VERSION ""

NS_ :

BS_:

BU_: BOOT STEER PEDAL TER_CMDS FRONT_AXLE IMU LVBMS ECU CHARGER TireTemps REFRI Control

BO_ 2147484162 BOOT_TX: 8 BOOT
 SG_ HEX_SIZE m1 : 40|24@1+ (1,0) [0|3] "" Vector__XXX
 SG_ HEX_CRC m1 : 8|32@1+ (1,0) [0|3] "" Vector__XXX
 SG_ NODE_ID : 4|4@1+ (1,0) [0|3] "" Vector__XXX
 SG_ BOOT_CMD M : 0|4@1+ (1,0) [0|3] "" Vector__XXX

BO_ 2147484161 BOOT_RX: 8 BOOT
 SG_ NACK m1 : 4|1@1+ (1,0) [0|1] "" Vector__XXX
 SG_ ACK m0 : 4|1@1+ (1,0) [0|1] "" Vector__XXX
 SG_ PERCENT m2 : 4|8@1+ (1,0) [0|1] "" Vector__XXX
 SG_ BOOT_CMD M : 0|4@1+ (1,0) [0|1] "" Vector__XXX

BO_ 2147484160 BOOT_DATA: 8 BOOT
 SG_ ADRESS : 32|32@1+ (1,0) [0|1] "" Vector__XXX
 SG_ DATA : 0|32@1+ (1,0) [0|1] "" Vector__XXX

BO_ 1 COMMAND: 8 TER_CMDS
 SG_ speedLimit m193 : 24|8@1+ (1,0) [1|120] "km/h" Vector__XXX
 SG_ cfgTractionControl m194 : 24|8@1+ (1,0) [0|1] "" Vector__XXX
 SG_ trqLimit m193 : 16|8@1+ (1,0) [1|180] "N/m" Vector__XXX
 SG_ cfgMode m194 : 16|8@1+ (1,0) [0|1] "" Vector__XXX
 SG_ kwLimit m193 : 8|8@1+ (1,0) [1|120] "kW" Vector__XXX
 SG_ cfgLimiter m194 : 8|8@1+ (1,0) [0|1] "" Vector__XXX
 SG_ VALUE m128 : 8|32@1+ (1,0) [0|1] "" Vector__XXX
 SG_ ONOFF m64 : 8|8@1+ (1,0) [0|1] "" Vector__XXX
 SG_ CMD M : 0|8@1+ (1,0) [0|1] "" Vector__XXX

BO_ 2 RESPONSE: 8 TER_CMDS
 SG_ CODE : 56|8@1+ (1,0) [0|1] "" Vector__XXX
 SG_ CMD M : 0|8@1+ (1,0) [0|1] "" Vector__XXX

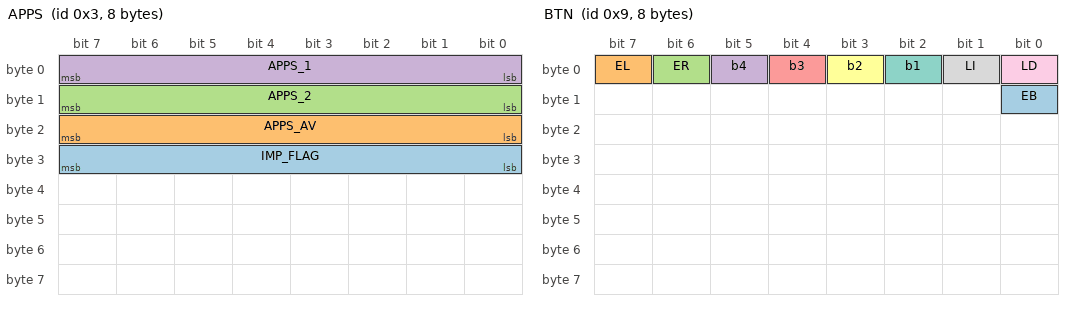
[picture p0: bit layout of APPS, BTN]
BO_ 3 APPS: 8 PEDAL
 SG_ IMP_FLAG : 24|8@1+ (1,0) [0|255] "" Vector__XXX
 SG_ APPS_AV : 16|8@1+ (1,0) [0|255] "" Vector__XXX
 SG_ APPS_2 : 8|8@1+ (1,0) [0|255] "" Vector__XXX
 SG_ APPS_1 : 0|8@1+ (1,0) [0|255] "" Vector__XXX

BO_ 4 BPPS: 8 PEDAL
 SG_ BPPS : 0|16@1+ (0.01,0) [0|1] "Bar" Vector__XXX

BO_ 5 STEER: 8 PEDAL
 SG_ ANGLE : 0|16@1- (1,0) [-360|360] "Grad" Vector__XXX

BO_ 9 BTN: 8 STEER
 SG_ EB : 8|1@1+ (1,0) [0|0] "" Vector__XXX
 SG_ EL : 7|1@1+ (1,0) [0|0] "" Vector__XXX
 SG_ ER : 6|1@1+ (1,0) [0|0] "" Vector__XXX
 SG_ b4 : 5|1@1+ (1,0) [0|0] "" Vector__XXX
 SG_ b3 : 4|1@1+ (1,0) [0|0] "" Vector__XXX
 SG_ b2 : 3|1@1+ (1,0) [0|0] "" Vector__XXX
 SG_ b1 : 2|1@1+ (1,0) [0|0] "" Vector__XXX
 SG_ LI : 1|1@1+ (1,0) [0|0] "" Vector__XXX
 SG_ LD : 0|1@1+ (1,0) [0|0] "" Vector__XXX

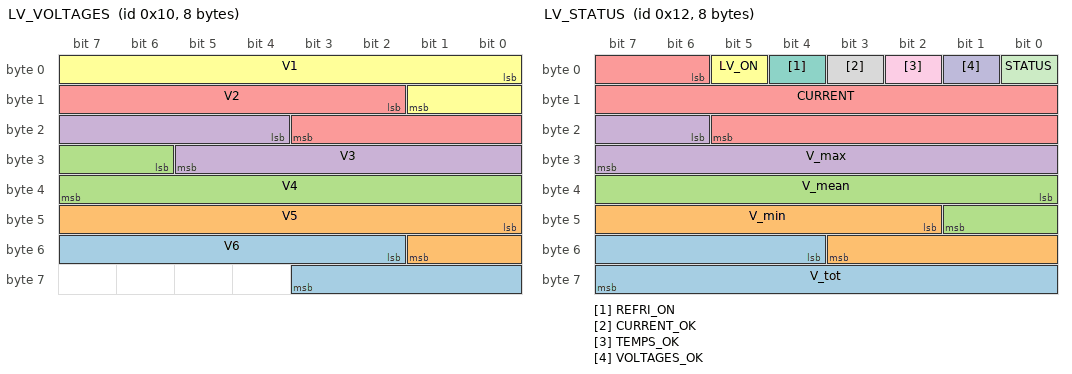
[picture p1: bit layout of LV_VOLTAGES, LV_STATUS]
BO_ 16 LV_VOLTAGES: 8 LVBMS
 SG_ V6 : 50|10@1+ (0.01,0) [0|1] "V" Vector__XXX
 SG_ V5 : 40|10@1+ (0.01,0) [0|1] "V" Vector__XXX
 SG_ V4 : 30|10@1+ (0.01,0) [0|1] "V" Vector__XXX
 SG_ V3 : 20|10@1+ (0.01,0) [0|1] "V" Vector__XXX
 SG_ V2 : 10|10@1+ (0.01,0) [0|1] "V" Vector__XXX
 SG_ V1 : 0|10@1+ (0.01,0) [0|1] "V" Vector__XXX

BO_ 17 LV_TEMPS: 6 LVBMS
 SG_ T3 : 32|16@1+ (0.1,0) [0|1] "Grad" Vector__XXX
 SG_ T2 : 16|16@1+ (0.1,0) [0|1] "Grad" Vector__XXX
 SG_ T1 : 0|16@1+ (0.1,0) [0|1] "Grad" Vector__XXX

BO_ 18 LV_STATUS: 8 LVBMS
 SG_ V_tot : 52|12@1+ (0.01,0) [0|0] "" Vector__XXX
 SG_ V_min : 42|10@1+ (0.01,0) [0|0] "" Vector__XXX
 SG_ V_mean : 32|10@1+ (0.01,0) [0|0] "" Vector__XXX
 SG_ V_max : 22|10@1+ (0.01,0) [0|0] "" Vector__XXX
 SG_ CURRENT : 6|16@1+ (0.1,0) [0|1] "A" Vector__XXX
 SG_ LV_ON : 5|1@1+ (1,0) [0|1] "" Vector__XXX
 SG_ REFRI_ON : 4|1@1+ (1,0) [0|1] "" Vector__XXX
 SG_ CURRENT_OK : 3|1@1+ (1,0) [0|0] "" Vector__XXX
 SG_ TEMPS_OK : 2|1@1+ (1,0) [0|1] "" Vector__XXX
 SG_ VOLTAGES_OK : 1|1@1+ (1,0) [0|0] "" Vector__XXX
 SG_ STATUS : 0|1@1+ (1,0) [0|0] "" Vector__XXX

BO_ 2147483667 LV_INFO: 8 LVBMS
 SG_ battDuration : 12|12@1+ (1,0) [0|1] "min" Vector__XXX
 SG_ SOC : 0|12@1+ (0.1,0) [0|1] "%" Vector__XXX

BO_ 35 Front_Susp: 8 FRONT_AXLE
 SG_ flDisp : 16|16@1- (0.1,0) [0|1] "mm" Vector__XXX
 SG_ frDisp : 0|16@1- (0.1,0) [0|1] "mm" Vector__XXX

BO_ 36 Front_TempsR: 8 FRONT_AXLE
 SG_ TempL : 16|16@1+ (0.1,0) [0|1] "grad" Vector__XXX
 SG_ TempR : 0|16@1+ (0.1,0) [0|1] "grad" Vector__XXX

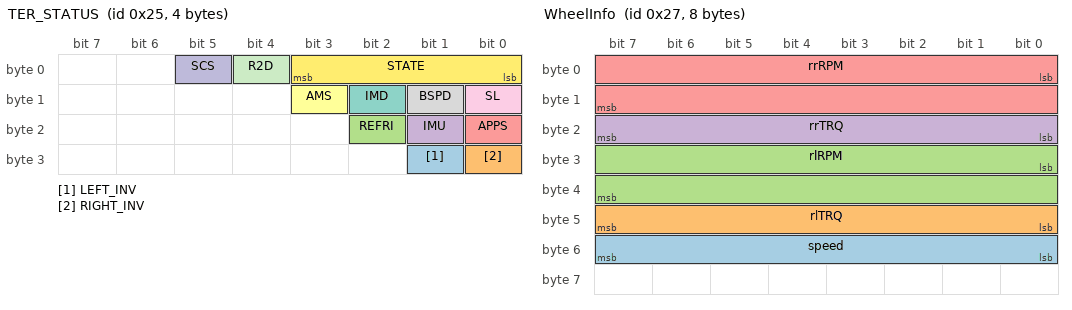
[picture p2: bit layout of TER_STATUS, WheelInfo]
BO_ 37 TER_STATUS: 4 ECU
 SG_ LEFT_INV : 25|1@1+ (1,0) [0|1] "" Vector__XXX
 SG_ RIGHT_INV : 24|1@1+ (1,0) [0|1] "" Vector__XXX
 SG_ REFRI : 18|1@1+ (1,0) [0|1] "" Vector__XXX
 SG_ IMU : 17|1@1+ (1,0) [0|1] "" Vector__XXX
 SG_ APPS : 16|1@1+ (1,0) [0|1] "" Vector__XXX
 SG_ AMS : 11|1@1+ (1,0) [0|1] "" Vector__XXX
 SG_ IMD : 10|1@1+ (1,0) [0|0] "" Vector__XXX
 SG_ BSPD : 9|1@1+ (1,0) [0|0] "" Vector__XXX
 SG_ SL : 8|1@1+ (1,0) [0|1] "" Vector__XXX
 SG_ SCS : 5|1@1+ (1,0) [0|1] "" Vector__XXX
 SG_ R2D : 4|1@1+ (1,0) [0|1] "" Vector__XXX
 SG_ STATE : 0|4@1+ (1,0) [0|1] "" Vector__XXX

BO_ 2147483686 ECU_CONFIG: 8 ECU
 SG_ TRQ_LIMIT m8 : 8|8@1+ (1,0) [0|1] "NM" Vector__XXX
 SG_ TRQ_KP m5 : 8|32@1- (1,0) [0|1] "" Vector__XXX
 SG_ TRQ_KI m6 : 8|32@1- (1,0) [0|1] "" Vector__XXX
 SG_ TRQ_KD m7 : 8|32@1- (1,0) [0|1] "" Vector__XXX
 SG_ TRACTION_CONTROL m4 : 8|8@1+ (1,0) [0|1] "" Vector__XXX
 SG_ SCS_ENABLE m0 : 8|1@1+ (1,0) [0|1] "" Vector__XXX
 SG_ REGEN_TRQ_SLOPE m24 : 8|8@1+ (1,0) [0|1] "" Vector__XXX
 SG_ REGEN_THR_SPEED m22 : 8|8@1+ (1,0) [0|1] "" Vector__XXX
 SG_ REGEN_THR_RPM m23 : 8|16@1+ (1,0) [0|1] "" Vector__XXX
 SG_ REGEN_MODE m25 : 8|8@1+ (1,0) [0|1] "" Vector__XXX
 SG_ REGEN_MAX_POSITIVE_TRQ_THR m26 : 8|8@1+ (1,0) [0|1] "" Vector__XXX
 SG_ REGEN_MAX_TRQ m18 : 8|8@1+ (1,0) [0|1] "" Vector__XXX
 SG_ REGEN_MAX_CURRENT m21 : 8|16@1- (1,0) [0|1] "" Vector__XXX
 SG_ REGEN_MAX_CELL_VOLT m19 : 8|16@1+ (1,0) [0|1] "mV" Vector__XXX
 SG_ REGEN_MAX_CELL_TEMP m20 : 8|8@1+ (1,0) [0|1] "" Vector__XXX
 SG_ REGEN_ENABLE m17 : 8|8@1+ (1,0) [0|1] "" Vector__XXX
 SG_ R2D_BRAKE m1 : 8|8@1+ (1,0) [0|1] "Bar" Vector__XXX
 SG_ LIMITER m2 : 8|8@1+ (1,0) [0|1] "" Vector__XXX
 SG_ FLAP_R_REVERSE m13 : 8|8@1+ (1,0) [0|1] "0" Vector__XXX
 SG_ FLAP_R_OFFSET m11 : 8|16@1- (1,0) [0|1] "Âº" Vector__XXX
 SG_ FLAP_PEDAL_SETPOINT m15 : 8|8@1+ (1,0) [0|1] "0" Vector__XXX
 SG_ FLAP_L_REVERSE m12 : 8|8@1+ (1,0) [0|1] "0" Vector__XXX
 SG_ FLAP_L_OFFSET m10 : 8|16@1- (1,0) [0|1] "Âº" Vector__XXX
 SG_ FLAP_ENABLE m14 : 8|8@1+ (1,0) [0|1] "0" Vector__XXX
 SG_ EEPROM m9 : 8|8@1+ (1,0) [0|1] "" Vector__XXX
 SG_ DRIVING_MODE m3 : 8|8@1+ (1,0) [0|1] "" Vector__XXX
 SG_ ENTRY M : 0|8@1+ (1,0) [0|1] "" Vector__XXX

BO_ 39 WheelInfo: 8 ECU
 SG_ speed : 48|8@1+ (1,0) [0|1] "" Vector__XXX
 SG_ rlTRQ : 40|8@1+ (1,0) [0|1] "" Vector__XXX
 SG_ rlRPM : 24|16@1- (1,0) [0|1] "" Vector__XXX
 SG_ rrTRQ : 16|8@1+ (1,0) [0|1] "" Vector__XXX
 SG_ rrRPM : 0|16@1- (1,0) [0|1] "" Vector__XXX

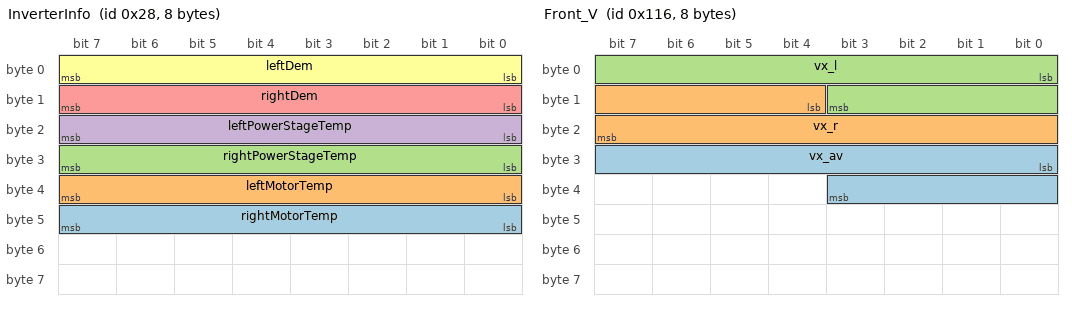
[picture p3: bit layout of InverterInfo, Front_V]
BO_ 40 InverterInfo: 8 ECU
 SG_ rightMotorTemp : 40|8@1+ (1,0) [0|1] "" Vector__XXX
 SG_ leftMotorTemp : 32|8@1+ (1,0) [0|1] "" Vector__XXX
 SG_ rightPowerStageTemp : 24|8@1+ (1,0) [0|1] "" Vector__XXX
 SG_ leftPowerStageTemp : 16|8@1+ (1,0) [0|1] "" Vector__XXX
 SG_ rightDem : 8|8@1+ (1,0) [0|1] "" Vector__XXX
 SG_ leftDem : 0|8@1+ (1,0) [0|1] "" Vector__XXX

BO_ 2147483689 Front_TempsL: 8 FRONT_AXLE
 SG_ TempL : 16|16@1+ (0.1,0) [0|1] "grad" Vector__XXX
 SG_ TempR : 0|16@1+ (0.1,0) [0|1] "grad" Vector__XXX

BO_ 2147483690 Rear_Susp: 8 FRONT_AXLE
 SG_ rrDisp : 16|16@1- (0.1,0) [0|1] "mm" Vector__XXX
 SG_ rlDisp : 0|16@1- (0.1,0) [0|1] "mm" Vector__XXX

BO_ 277 Front_RPM: 8 FRONT_AXLE
 SG_ RPM_R : 16|16@1+ (1,0) [0|1] "" Vector__XXX
 SG_ RPM_L : 0|16@1+ (1,0) [0|1] "" Vector__XXX

BO_ 278 Front_V: 8 FRONT_AXLE
 SG_ vx_av : 24|12@1+ (0.01,0) [0|1] "" Vector__XXX
 SG_ vx_r : 12|12@1+ (0.01,0) [0|1] "" Vector__XXX
 SG_ vx_l : 0|12@1+ (0.01,0) [0|1] "" Vector__XXX

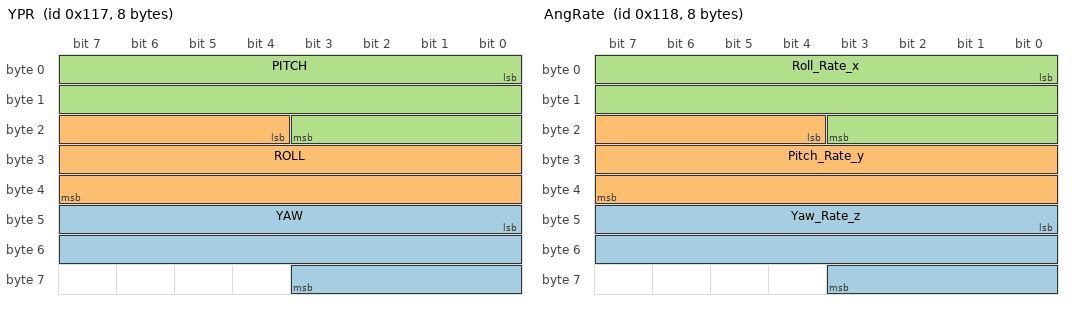
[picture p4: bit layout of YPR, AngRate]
BO_ 279 YPR: 8 IMU
 SG_ YAW : 40|20@1- (0.01,0) [0|1] "" Vector__XXX
 SG_ ROLL : 20|20@1- (0.01,0) [0|1] "" Vector__XXX
 SG_ PITCH : 0|20@1- (0.01,0) [0|1] "" Vector__XXX

BO_ 280 AngRate: 8 IMU
 SG_ Yaw_Rate_z : 40|20@1- (0.001,0) [0|1] "" Vector__XXX
 SG_ Pitch_Rate_y : 20|20@1- (0.001,0) [0|1] "" Vector__XXX
 SG_ Roll_Rate_x : 0|20@1- (0.001,0) [0|1] "" Vector__XXX

BO_ 281 GPS_Lat_Long: 8 IMU
 SG_ Longitude : 32|32@1- (1e-07,0) [0|1] "" Vector__XXX
 SG_ Latitude : 0|32@1- (1e-07,0) [0|1] "" Vector__XXX

BO_ 288 GPS_Altitude_Pres: 8 IMU
 SG_ Barometric_Pressure : 32|16@1- (1e-07,0) [0|1] "" Vector__XXX
 SG_ Altidude : 0|32@1- (1e-07,0) [0|1] "" Vector__XXX

BO_ 289 Accel: 8 IMU
 SG_ a_z : 32|16@1- (0.001,0) [0|1] "" Vector__XXX
 SG_ a_y : 16|16@1- (0.001,0) [0|1] "" Vector__XXX
 SG_ a_x : 0|16@1- (0.001,0) [0|1] "" Vector__XXX

BO_ 290 Mag: 8 IMU
 SG_ Heading : 0|16@1- (0.01,0) [0|1] "" Vector__XXX

BO_ 291 VelBody: 8 IMU
 SG_ v_z : 32|16@1- (0.001,0) [0|1] "" Vector__XXX
 SG_ v_y : 16|16@1- (0.001,0) [0|1] "" Vector__XXX
 SG_ v_x : 0|16@1- (0.001,0) [0|1] "" Vector__XXX

BO_ 292 ImuStatus: 8 IMU
 SG_ VelU : 32|16@1- (0.001,0) [0|1] "" Vector__XXX
 SG_ PosU : 16|16@1- (0.001,0) [0|1] "" Vector__XXX
 SG_ Status : 0|16@1- (1,0) [0|1] "" Vector__XXX

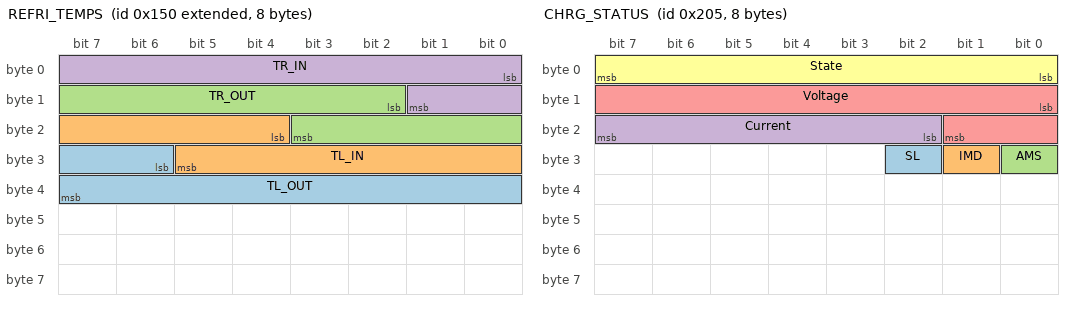
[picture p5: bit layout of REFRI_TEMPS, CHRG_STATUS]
BO_ 2147483984 REFRI_TEMPS: 8 REFRI
 SG_ TL_OUT : 30|10@1+ (0.1,0) [0|1] "C" Vector__XXX
 SG_ TL_IN : 20|10@1+ (0.1,0) [0|1] "C" Vector__XXX
 SG_ TR_OUT : 10|10@1+ (0.1,0) [0|1] "C" Vector__XXX
 SG_ TR_IN : 0|10@1+ (0.1,0) [0|1] "C" Vector__XXX

BO_ 2147483985 REFRI_CONFIG: 8 REFRI
 SG_ TARGET_TEMP_ACCU m7 : 8|8@1+ (1,0) [0|1] "ÂºC" Vector__XXX
 SG_ TARGET_TEMP m3 : 8|8@1+ (1,0) [0|1] "ÂºC" Vector__XXX
 SG_ POWER_ACCU m4 : 8|8@1+ (1,0) [0|1] "" Vector__XXX
 SG_ POWER m0 : 8|8@1+ (1,0) [0|1] "" Vector__XXX
 SG_ MODE_ACCU m6 : 8|8@1+ (1,0) [0|1] "" Vector__XXX
 SG_ MODE m2 : 8|8@1+ (1,0) [0|1] "" Vector__XXX
 SG_ INTENSITY_ACCU m5 : 8|8@1+ (1,0) [0|100] "%" Vector__XXX
 SG_ INTENSITY m1 : 8|8@1+ (1,0) [0|100] "%" Vector__XXX
 SG_ ENTRY M : 0|8@1+ (1,0) [0|1] "" Vector__XXX

BO_ 2147483986 REFRI_RPM: 8 REFRI
 SG_ ACCU_RPM : 32|16@1+ (1,0) [0|1] "rpm" Vector__XXX
 SG_ R_RPM : 16|16@1+ (1,0) [0|1] "rpm" Vector__XXX
 SG_ L_RPM : 0|16@1+ (1,0) [0|1] "rpm" Vector__XXX

BO_ 2147483987 REFRI_STATUS: 8 REFRI
 SG_ MODE : 16|2@1+ (1,0) [0|1] "" Vector__XXX
 SG_ CURRENT : 0|16@1+ (0.1,0) [0|1] "" Vector__XXX

BO_ 517 CHRG_STATUS: 8 CHARGER
 SG_ SL : 26|1@1+ (1,0) [0|1] "A" Vector__XXX
 SG_ IMD : 25|1@1+ (1,0) [0|1] "A" Vector__XXX
 SG_ AMS : 24|1@1+ (1,0) [0|1] "A" Vector__XXX
 SG_ Current : 18|6@1+ (1,0) [0|1] "A" Vector__XXX
 SG_ Voltage : 8|10@1+ (1,0) [0|1] "V" Vector__XXX
 SG_ State : 0|8@1+ (1,0) [0|1] "" Vector__XXX

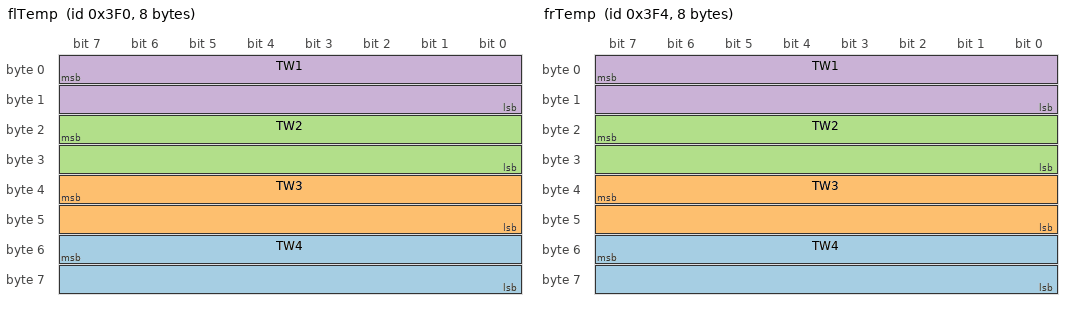
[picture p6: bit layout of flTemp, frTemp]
BO_ 1008 flTemp: 8 TireTemps
 SG_ TW4 : 55|16@0- (0.1,0) [-3276.8|3276.7] "" Vector__XXX
 SG_ TW3 : 39|16@0- (0.1,0) [-3276.8|3276.7] "" Vector__XXX
 SG_ TW2 : 23|16@0- (0.1,0) [-3276.8|3276.7] "" Vector__XXX
 SG_ TW1 : 7|16@0- (0.1,0) [-3276.8|3276.7] "" Vector__XXX

BO_ 1012 frTemp: 8 TireTemps
 SG_ TW4 : 55|16@0- (0.1,0) [-3276.8|3276.7] "" Vector__XXX
 SG_ TW3 : 39|16@0- (0.1,0) [-3276.8|3276.7] "" Vector__XXX
 SG_ TW2 : 23|16@0- (0.1,0) [-3276.8|3276.7] "" Vector__XXX
 SG_ TW1 : 7|16@0- (0.1,0) [-3276.8|3276.7] "" Vector__XXX

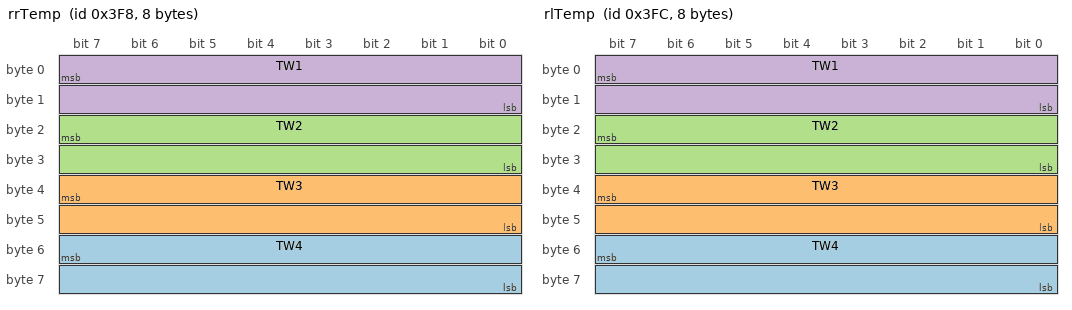
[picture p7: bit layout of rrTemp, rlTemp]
BO_ 1016 rrTemp: 8 TireTemps
 SG_ TW4 : 55|16@0- (0.1,0) [-3276.8|3276.7] "" Vector__XXX
 SG_ TW3 : 39|16@0- (0.1,0) [-3276.8|3276.7] "" Vector__XXX
 SG_ TW2 : 23|16@0- (0.1,0) [-3276.8|3276.7] "" Vector__XXX
 SG_ TW1 : 7|16@0- (0.1,0) [-3276.8|3276.7] "" Vector__XXX

BO_ 1020 rlTemp: 8 TireTemps
 SG_ TW4 : 55|16@0- (0.1,0) [-3276.8|3276.7] "" Vector__XXX
 SG_ TW3 : 39|16@0- (0.1,0) [-3276.8|3276.7] "" Vector__XXX
 SG_ TW2 : 23|16@0- (0.1,0) [-3276.8|3276.7] "" Vector__XXX
 SG_ TW1 : 7|16@0- (0.1,0) [-3276.8|3276.7] "" Vector__XXX

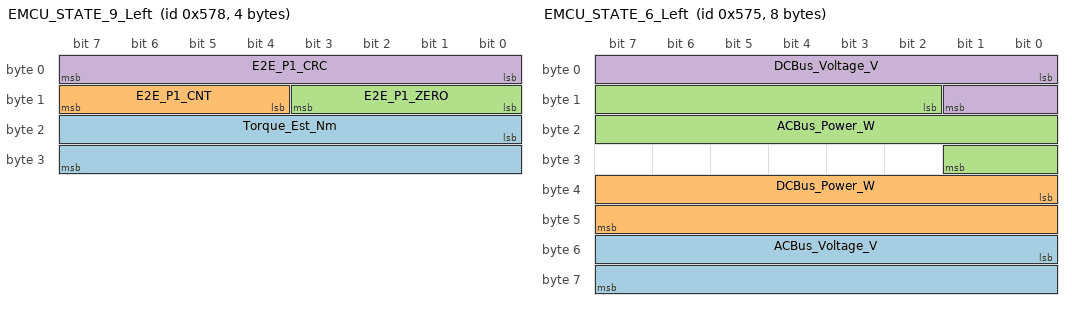
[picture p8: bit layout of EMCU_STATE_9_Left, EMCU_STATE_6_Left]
BO_ 1400 EMCU_STATE_9_Left: 4 Vector__XXX
 SG_ Torque_Est_Nm : 16|16@1- (1,0) [-32768|32767] "" Vector__XXX
 SG_ E2E_P1_CNT : 12|4@1+ (1,0) [0|15] "" Vector__XXX
 SG_ E2E_P1_ZERO : 8|4@1+ (1,0) [0|15] "" Vector__XXX
 SG_ E2E_P1_CRC : 0|8@1+ (1,0) [0|255] "" Vector__XXX

BO_ 1399 EMCU_STATE_8_Left: 6 Vector__XXX
 SG_ Setpoint_App_Q_A : 32|16@1- (0.03125,0) [-1024|1023.97] "" Vector__XXX
 SG_ Setpoint_App_D_A : 16|16@1- (0.03125,0) [-1024|1023.97] "" Vector__XXX
 SG_ Torque_Max_Feas_Ndm : 0|16@1- (1,0) [-32768|32767] "" Vector__XXX

BO_ 1398 EMCU_STATE_7_Left: 2 Vector__XXX
 SG_ Dem : 0|16@1+ (1,0) [0|65535] "" Vector__XXX

BO_ 1397 EMCU_STATE_6_Left: 8 Vector__XXX
 SG_ ACBus_Voltage_V : 48|16@1- (1,0) [-32768|32767] "" Vector__XXX
 SG_ DCBus_Power_W : 32|16@1- (1,0) [-32768|32767] "" Vector__XXX
 SG_ ACBus_Power_W : 10|16@1- (32.767,0) [-1073710|1073680] "" Vector__XXX
 SG_ DCBus_Voltage_V : 0|10@1+ (1,0) [0|1023] "" Vector__XXX

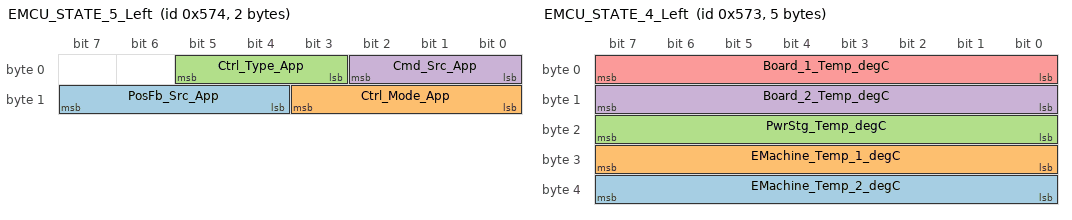
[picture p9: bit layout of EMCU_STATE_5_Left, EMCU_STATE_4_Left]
BO_ 1396 EMCU_STATE_5_Left: 2 Vector__XXX
 SG_ PosFb_Src_App : 12|4@1+ (1,0) [0|15] "" Vector__XXX
 SG_ Ctrl_Mode_App : 8|4@1+ (1,0) [0|15] "" Vector__XXX
 SG_ Ctrl_Type_App : 3|3@1+ (1,0) [0|7] "" Vector__XXX
 SG_ Cmd_Src_App : 0|3@1+ (1,0) [0|7] "" Vector__XXX

BO_ 1395 EMCU_STATE_4_Left: 5 Vector__XXX
 SG_ EMachine_Temp_2_degC : 32|8@1- (1,80) [-48|207] "" Vector__XXX
 SG_ EMachine_Temp_1_degC : 24|8@1- (1,80) [-48|207] "" Vector__XXX
 SG_ PwrStg_Temp_degC : 16|8@1- (1,80) [-48|207] "" Vector__XXX
 SG_ Board_2_Temp_degC : 8|8@1- (1,80) [-48|207] "" Vector__XXX
 SG_ Board_1_Temp_degC : 0|8@1- (1,80) [-48|207] "" Vector__XXX

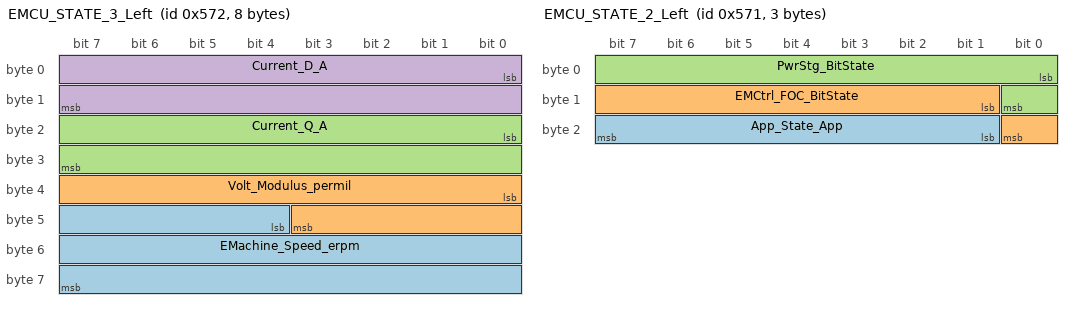
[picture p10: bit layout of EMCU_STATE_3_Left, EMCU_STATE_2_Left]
BO_ 1394 EMCU_STATE_3_Left: 8 Vector__XXX
 SG_ EMachine_Speed_erpm : 44|20@1- (1,0) [-524288|524287] "" Vector__XXX
 SG_ Volt_Modulus_permil : 32|12@1+ (1,0) [0|4095] "" Vector__XXX
 SG_ Current_Q_A : 16|16@1- (0.03125,0) [-1024|1023.97] "" Vector__XXX
 SG_ Current_D_A : 0|16@1- (0.03125,0) [-1024|1023.97] "" Vector__XXX

BO_ 1393 EMCU_STATE_2_Left: 3 Vector__XXX
 SG_ App_State_App : 17|7@1+ (1,0) [0|127] "" Vector__XXX
 SG_ EMCtrl_FOC_BitState : 9|8@1+ (1,0) [0|255] "" Vector__XXX
 SG_ PwrStg_BitState : 0|9@1+ (1,0) [0|511] "" Vector__XXX

BO_ 1392 EMCU_STATE_1_Left: 5 Vector__XXX
 SG_ CPU_Load : 32|8@1+ (1,0) [0|255] "" Vector__XXX
 SG_ Uptime_ms : 0|32@1+ (1,0) [0|2704] "" Vector__XXX

BO_ 1653 EMCU_SETPOINT_6_Left: 2 Vector__XXX
 SG_ PWM_Freq_KHz : 0|16@1+ (1,0) [0|65535] "" Vector__XXX

BO_ 1651 EMCU_SETPOINT_4_Left: 4 Vector__XXX
 SG_ Speed_erpm : 0|32@1- (1,0) [-2147480000|2147480000] "" Vector__XXX

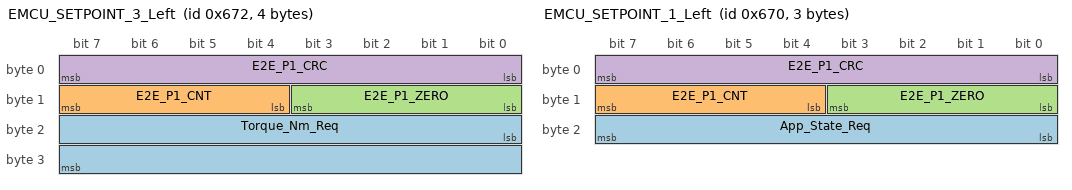
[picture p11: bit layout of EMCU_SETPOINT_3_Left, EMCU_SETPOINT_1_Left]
BO_ 1650 EMCU_SETPOINT_3_Left: 4 Vector__XXX
 SG_ Torque_Nm_Req : 16|16@1- (1,0) [-32768|32767] "" Vector__XXX
 SG_ E2E_P1_CNT : 12|4@1+ (1,0) [0|15] "" Vector__XXX
 SG_ E2E_P1_ZERO : 8|4@1+ (1,0) [0|15] "" Vector__XXX
 SG_ E2E_P1_CRC : 0|8@1+ (1,0) [0|255] "" Vector__XXX

BO_ 1649 EMCU_SETPOINT_2_Left: 4 Vector__XXX
 SG_ Current_Q_A_Req : 16|16@1- (0.03125,0) [-1024|1023.97] "" Vector__XXX
 SG_ Current_D_A_Req : 0|16@1- (0.03125,0) [-1024|1023.97] "" Vector__XXX

BO_ 1648 EMCU_SETPOINT_1_Left: 3 Vector__XXX
 SG_ App_State_Req : 16|8@1+ (1,0) [0|255] "" Vector__XXX
 SG_ E2E_P1_CNT : 12|4@1+ (1,0) [0|15] "" Vector__XXX
 SG_ E2E_P1_ZERO : 8|4@1+ (1,0) [0|15] "" Vector__XXX
 SG_ E2E_P1_CRC : 0|8@1+ (1,0) [0|255] "" Vector__XXX

BO_ 2147485552 EMCU_DEBUG_1_Left: 2 Vector__XXX
 SG_ EMachine_Angle_fract16 : 0|16@1+ (1,0) [0|65535] "" Vector__XXX

BO_ 1376 EMCU_STATE_1_Right: 5 Vector__XXX
 SG_ CPU_Load : 32|8@1+ (1,0) [0|255] "" Vector__XXX
 SG_ Uptime_ms : 0|32@1+ (1,0) [0|2704] "" Vector__XXX

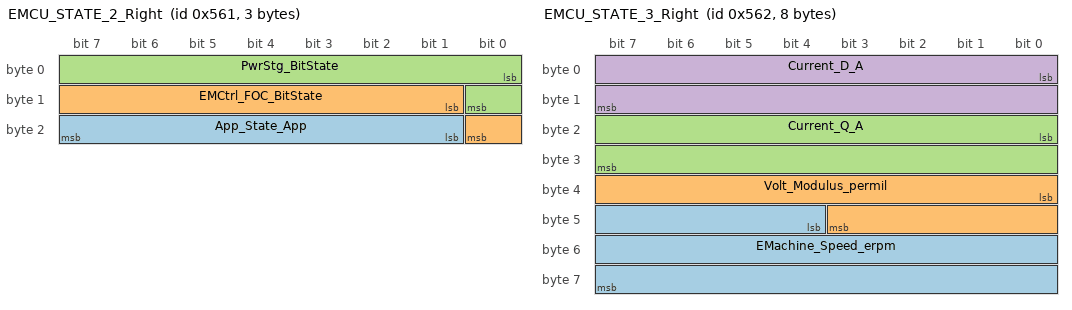
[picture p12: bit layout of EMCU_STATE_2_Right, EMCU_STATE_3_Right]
BO_ 1377 EMCU_STATE_2_Right: 3 Vector__XXX
 SG_ App_State_App : 17|7@1+ (1,0) [0|127] "" Vector__XXX
 SG_ EMCtrl_FOC_BitState : 9|8@1+ (1,0) [0|255] "" Vector__XXX
 SG_ PwrStg_BitState : 0|9@1+ (1,0) [0|511] "" Vector__XXX

BO_ 1378 EMCU_STATE_3_Right: 8 Vector__XXX
 SG_ EMachine_Speed_erpm : 44|20@1- (1,0) [-524288|524287] "" Vector__XXX
 SG_ Volt_Modulus_permil : 32|12@1+ (1,0) [0|4095] "" Vector__XXX
 SG_ Current_Q_A : 16|16@1- (0.03125,0) [-1024|1023.97] "" Vector__XXX
 SG_ Current_D_A : 0|16@1- (0.03125,0) [-1024|1023.97] "" Vector__XXX

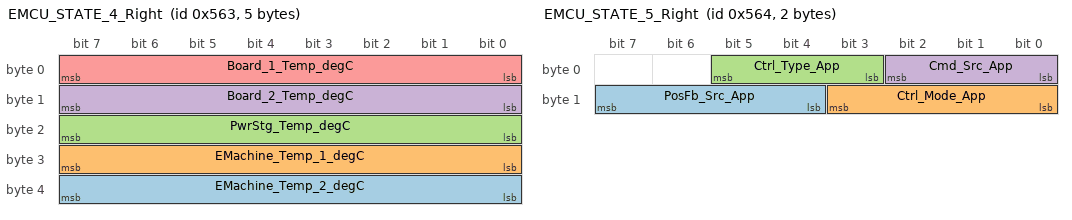
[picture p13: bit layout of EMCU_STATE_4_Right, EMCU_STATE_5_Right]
BO_ 1379 EMCU_STATE_4_Right: 5 Vector__XXX
 SG_ EMachine_Temp_2_degC : 32|8@1- (1,80) [-48|207] "" Vector__XXX
 SG_ EMachine_Temp_1_degC : 24|8@1- (1,80) [-48|207] "" Vector__XXX
 SG_ PwrStg_Temp_degC : 16|8@1- (1,80) [-48|207] "" Vector__XXX
 SG_ Board_2_Temp_degC : 8|8@1- (1,80) [-48|207] "" Vector__XXX
 SG_ Board_1_Temp_degC : 0|8@1- (1,80) [-48|207] "" Vector__XXX

BO_ 1380 EMCU_STATE_5_Right: 2 Vector__XXX
 SG_ PosFb_Src_App : 12|4@1+ (1,0) [0|15] "" Vector__XXX
 SG_ Ctrl_Mode_App : 8|4@1+ (1,0) [0|15] "" Vector__XXX
 SG_ Ctrl_Type_App : 3|3@1+ (1,0) [0|7] "" Vector__XXX
 SG_ Cmd_Src_App : 0|3@1+ (1,0) [0|7] "" Vector__XXX

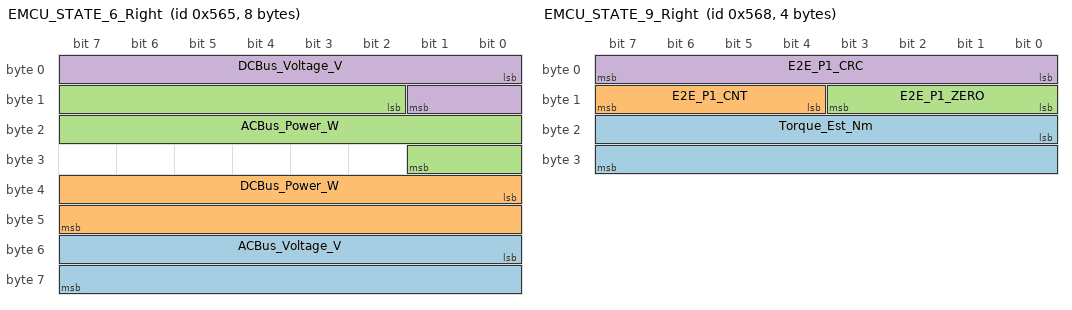
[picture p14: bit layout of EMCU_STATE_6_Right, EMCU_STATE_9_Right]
BO_ 1381 EMCU_STATE_6_Right: 8 Vector__XXX
 SG_ ACBus_Voltage_V : 48|16@1- (1,0) [-32768|32767] "" Vector__XXX
 SG_ DCBus_Power_W : 32|16@1- (1,0) [-32768|32767] "" Vector__XXX
 SG_ ACBus_Power_W : 10|16@1- (32.767,0) [-1073710|1073680] "" Vector__XXX
 SG_ DCBus_Voltage_V : 0|10@1+ (1,0) [0|1023] "" Vector__XXX

BO_ 1382 EMCU_STATE_7_Right: 2 Vector__XXX
 SG_ Dem : 0|16@1+ (1,0) [0|65535] "" Vector__XXX

BO_ 1383 EMCU_STATE_8_Right: 6 Vector__XXX
 SG_ Setpoint_App_Q_A : 32|16@1- (0.03125,0) [-1024|1023.97] "" Vector__XXX
 SG_ Setpoint_App_D_A : 16|16@1- (0.03125,0) [-1024|1023.97] "" Vector__XXX
 SG_ Torque_Max_Feas_Ndm : 0|16@1- (1,0) [-32768|32767] "" Vector__XXX

BO_ 1384 EMCU_STATE_9_Right: 4 Vector__XXX
 SG_ Torque_Est_Nm : 16|16@1- (1,0) [-32768|32767] "" Vector__XXX
 SG_ E2E_P1_CNT : 12|4@1+ (1,0) [0|15] "" Vector__XXX
 SG_ E2E_P1_ZERO : 8|4@1+ (1,0) [0|15] "" Vector__XXX
 SG_ E2E_P1_CRC : 0|8@1+ (1,0) [0|255] "" Vector__XXX

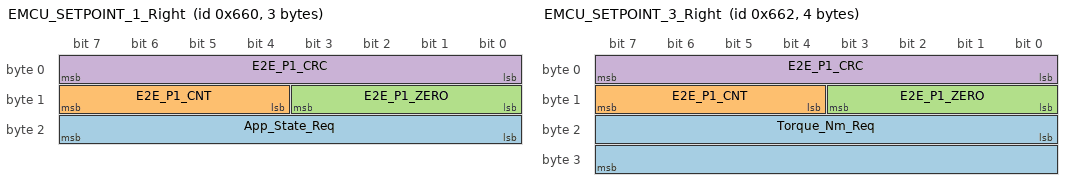
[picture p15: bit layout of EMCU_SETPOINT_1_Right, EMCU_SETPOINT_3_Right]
BO_ 1632 EMCU_SETPOINT_1_Right: 3 Vector__XXX
 SG_ App_State_Req : 16|8@1+ (1,0) [0|255] "" Vector__XXX
 SG_ E2E_P1_CNT : 12|4@1+ (1,0) [0|15] "" Vector__XXX
 SG_ E2E_P1_ZERO : 8|4@1+ (1,0) [0|15] "" Vector__XXX
 SG_ E2E_P1_CRC : 0|8@1+ (1,0) [0|255] "" Vector__XXX

BO_ 1633 EMCU_SETPOINT_2_Right: 4 Vector__XXX
 SG_ Current_Q_A_Req : 16|16@1- (0.03125,0) [-1024|1023.97] "" Vector__XXX
 SG_ Current_D_A_Req : 0|16@1- (0.03125,0) [-1024|1023.97] "" Vector__XXX

BO_ 1634 EMCU_SETPOINT_3_Right: 4 Vector__XXX
 SG_ Torque_Nm_Req : 16|16@1- (1,0) [-32768|32767] "" Vector__XXX
 SG_ E2E_P1_CNT : 12|4@1+ (1,0) [0|15] "" Vector__XXX
 SG_ E2E_P1_ZERO : 8|4@1+ (1,0) [0|15] "" Vector__XXX
 SG_ E2E_P1_CRC : 0|8@1+ (1,0) [0|255] "" Vector__XXX

BO_ 1635 EMCU_SETPOINT_4_Right: 4 Vector__XXX
 SG_ Speed_erpm : 0|32@1- (1,0) [-2147480000|2147480000] "" Vector__XXX

BO_ 1637 EMCU_SETPOINT_6_Right: 2 Vector__XXX
 SG_ PWM_Freq_KHz : 0|16@1+ (1,0) [0|65535] "" Vector__XXX

BO_ 2147485536 EMCU_DEBUG_1_Right: 2 Vector__XXX
 SG_ EMachine_Angle_fract16 : 0|16@1+ (1,0) [0|65535] "" Vector__XXX

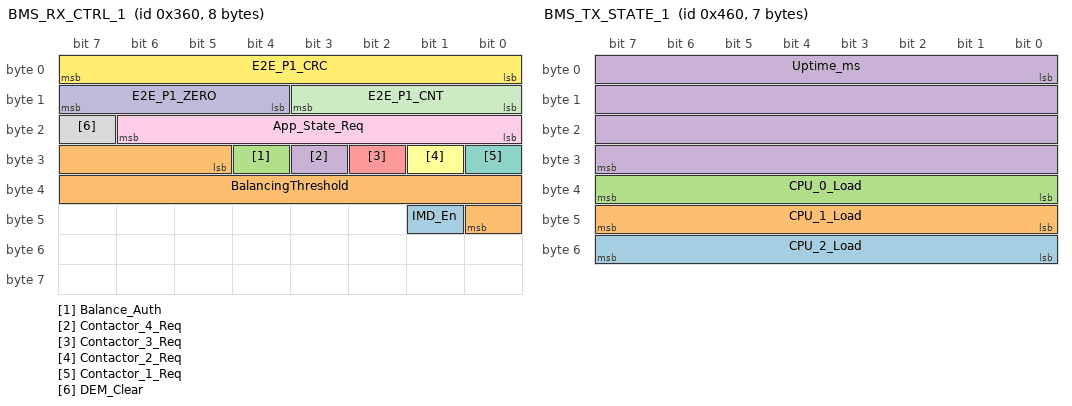
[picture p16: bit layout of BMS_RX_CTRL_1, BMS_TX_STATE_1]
BO_ 864 BMS_RX_CTRL_1: 8 Vector__XXX
 SG_ IMD_En : 41|1@1+ (1,0) [0|1] "" Vector__XXX
 SG_ BalancingThreshold : 29|12@1+ (1,405) [405|4500] "" Vector__XXX
 SG_ Balance_Auth : 28|1@1- (1,0) [0|1] "" Vector__XXX
 SG_ Contactor_4_Req : 27|1@1- (1,0) [0|1] "" Vector__XXX
 SG_ Contactor_3_Req : 26|1@1- (1,0) [0|1] "" Vector__XXX
 SG_ Contactor_2_Req : 25|1@1- (1,0) [0|1] "" Vector__XXX
 SG_ Contactor_1_Req : 24|1@1- (1,0) [0|1] "" Vector__XXX
 SG_ DEM_Clear : 23|1@1+ (1,0) [0|1] "" Vector__XXX
 SG_ App_State_Req : 16|7@1+ (1,0) [0|255] "" Vector__XXX
 SG_ E2E_P1_ZERO : 12|4@1+ (1,0) [0|15] "" Vector__XXX
 SG_ E2E_P1_CNT : 8|4@1+ (1,0) [0|15] "" Vector__XXX
 SG_ E2E_P1_CRC : 0|8@1+ (1,0) [0|255] "" Vector__XXX

BO_ 1024 BMS_TX_CMD_1: 6 Vector__XXX
 SG_ CellTemp4 m6 : 32|8@1+ (1,-40) [-40|140] "" Vector__XXX
 SG_ Cell9 m2 : 32|12@1+ (1,405) [405|4500] "" Vector__XXX
 SG_ Cell6 m1 : 32|12@1+ (1,405) [405|4500] "" Vector__XXX
 SG_ Cell3 m0 : 32|12@1+ (1,405) [405|4500] "" Vector__XXX
 SG_ Cell18 m5 : 32|12@1+ (1,405) [405|4500] "" Vector__XXX
 SG_ Cell15 m4 : 32|12@1+ (1,405) [405|4500] "" Vector__XXX
 SG_ Cell12 m3 : 32|12@1+ (1,405) [405|4500] "" Vector__XXX
 SG_ CellTemp3 m6 : 24|8@1+ (1,-40) [-40|140] "" Vector__XXX
 SG_ Cell8 m2 : 20|12@1+ (1,405) [405|4500] "" Vector__XXX
 SG_ Cell5 m1 : 20|12@1+ (1,405) [405|4500] "" Vector__XXX
 SG_ Cell2 m0 : 20|12@1+ (1,405) [405|4500] "" Vector__XXX
 SG_ Cell17 m5 : 20|12@1+ (1,405) [405|4500] "" Vector__XXX
 SG_ Cell14 m4 : 20|12@1+ (1,405) [405|4500] "" Vector__XXX
 SG_ Cell11 m3 : 20|12@1+ (1,405) [405|4500] "" Vector__XXX
 SG_ CellTemp2 m6 : 16|8@1+ (1,-40) [-40|140] "" Vector__XXX
 SG_ CellTemp1 m6 : 8|8@1+ (1,-40) [-40|140] "" Vector__XXX
 SG_ Cell7 m2 : 8|12@1+ (1,405) [405|4500] "" Vector__XXX
 SG_ Cell4 m1 : 8|12@1+ (1,405) [405|4500] "" Vector__XXX
 SG_ Cell16 m5 : 8|12@1+ (1,405) [405|4500] "" Vector__XXX
 SG_ Cell13 m4 : 8|12@1+ (1,405) [405|4500] "" Vector__XXX
 SG_ Cell10 m3 : 8|12@1+ (1,405) [405|4500] "" Vector__XXX
 SG_ Cell1 m0 : 8|12@1+ (1,405) [405|4500] "" Vector__XXX
 SG_ Cell_Cnt : 4|4@1+ (1,0) [0|15] "" Vector__XXX
 SG_ Cell_Idx M : 0|4@1+ (1,0) [0|4095] "" Vector__XXX

BO_ 1025 BMS_TX_CMD_2: 6 Vector__XXX
 SG_ CellTemp4 m6 : 32|8@1+ (1,-40) [-40|140] "" Vector__XXX
 SG_ Cell9 m2 : 32|12@1+ (1,405) [405|4500] "" Vector__XXX
 SG_ Cell6 m1 : 32|12@1+ (1,405) [405|4500] "" Vector__XXX
 SG_ Cell3 m0 : 32|12@1+ (1,405) [405|4500] "" Vector__XXX
 SG_ Cell18 m5 : 32|12@1+ (1,405) [405|4500] "" Vector__XXX
 SG_ Cell15 m4 : 32|12@1+ (1,405) [405|4500] "" Vector__XXX
 SG_ Cell12 m3 : 32|12@1+ (1,405) [405|4500] "" Vector__XXX
 SG_ CellTemp3 m6 : 24|8@1+ (1,-40) [-40|140] "" Vector__XXX
 SG_ Cell8 m2 : 20|12@1+ (1,405) [405|4500] "" Vector__XXX
 SG_ Cell5 m1 : 20|12@1+ (1,405) [405|4500] "" Vector__XXX
 SG_ Cell2 m0 : 20|12@1+ (1,405) [405|4500] "" Vector__XXX
 SG_ Cell17 m5 : 20|12@1+ (1,405) [405|4500] "" Vector__XXX
 SG_ Cell14 m4 : 20|12@1+ (1,405) [405|4500] "" Vector__XXX
 SG_ Cell11 m3 : 20|12@1+ (1,405) [405|4500] "" Vector__XXX
 SG_ CellTemp2 m6 : 16|8@1+ (1,-40) [-40|140] "" Vector__XXX
 SG_ CellTemp1 m6 : 8|8@1+ (1,-40) [-40|140] "" Vector__XXX
 SG_ Cell7 m2 : 8|12@1+ (1,405) [405|4500] "" Vector__XXX
 SG_ Cell4 m1 : 8|12@1+ (1,405) [405|4500] "" Vector__XXX
 SG_ Cell16 m5 : 8|12@1+ (1,405) [405|4500] "" Vector__XXX
 SG_ Cell13 m4 : 8|12@1+ (1,405) [405|4500] "" Vector__XXX
 SG_ Cell10 m3 : 8|12@1+ (1,405) [405|4500] "" Vector__XXX
 SG_ Cell1 m0 : 8|12@1+ (1,405) [405|4500] "" Vector__XXX
 SG_ Cell_Cnt : 4|4@1+ (1,0) [0|15] "" Vector__XXX
 SG_ Cell_Idx M : 0|4@1+ (1,0) [0|4095] "" Vector__XXX

BO_ 1026 BMS_TX_CMD_3: 6 Vector__XXX
 SG_ CellTemp4 m6 : 32|8@1+ (1,-40) [-40|140] "" Vector__XXX
 SG_ Cell9 m2 : 32|12@1+ (1,405) [405|4500] "" Vector__XXX
 SG_ Cell6 m1 : 32|12@1+ (1,405) [405|4500] "" Vector__XXX
 SG_ Cell3 m0 : 32|12@1+ (1,405) [405|4500] "" Vector__XXX
 SG_ Cell18 m5 : 32|12@1+ (1,405) [405|4500] "" Vector__XXX
 SG_ Cell15 m4 : 32|12@1+ (1,405) [405|4500] "" Vector__XXX
 SG_ Cell12 m3 : 32|12@1+ (1,405) [405|4500] "" Vector__XXX
 SG_ CellTemp3 m6 : 24|8@1+ (1,-40) [-40|140] "" Vector__XXX
 SG_ Cell8 m2 : 20|12@1+ (1,405) [405|4500] "" Vector__XXX
 SG_ Cell5 m1 : 20|12@1+ (1,405) [405|4500] "" Vector__XXX
 SG_ Cell2 m0 : 20|12@1+ (1,405) [405|4500] "" Vector__XXX
 SG_ Cell17 m5 : 20|12@1+ (1,405) [405|4500] "" Vector__XXX
 SG_ Cell14 m4 : 20|12@1+ (1,405) [405|4500] "" Vector__XXX
 SG_ Cell11 m3 : 20|12@1+ (1,405) [405|4500] "" Vector__XXX
 SG_ CellTemp2 m6 : 16|8@1+ (1,-40) [-40|140] "" Vector__XXX
 SG_ CellTemp1 m6 : 8|8@1+ (1,-40) [-40|140] "" Vector__XXX
 SG_ Cell7 m2 : 8|12@1+ (1,405) [405|4500] "" Vector__XXX
 SG_ Cell4 m1 : 8|12@1+ (1,405) [405|4500] "" Vector__XXX
 SG_ Cell16 m5 : 8|12@1+ (1,405) [405|4500] "" Vector__XXX
 SG_ Cell13 m4 : 8|12@1+ (1,405) [405|4500] "" Vector__XXX
 SG_ Cell10 m3 : 8|12@1+ (1,405) [405|4500] "" Vector__XXX
 SG_ Cell1 m0 : 8|12@1+ (1,405) [405|4500] "" Vector__XXX
 SG_ Cell_Cnt : 4|4@1+ (1,0) [0|15] "" Vector__XXX
 SG_ Cell_Idx M : 0|4@1+ (1,0) [0|4095] "" Vector__XXX

BO_ 1027 BMS_TX_CMD_4: 6 Vector__XXX
 SG_ CellTemp4 m6 : 32|8@1+ (1,-40) [-40|140] "" Vector__XXX
 SG_ Cell9 m2 : 32|12@1+ (1,405) [405|4500] "" Vector__XXX
 SG_ Cell6 m1 : 32|12@1+ (1,405) [405|4500] "" Vector__XXX
 SG_ Cell3 m0 : 32|12@1+ (1,405) [405|4500] "" Vector__XXX
 SG_ Cell18 m5 : 32|12@1+ (1,405) [405|4500] "" Vector__XXX
 SG_ Cell15 m4 : 32|12@1+ (1,405) [405|4500] "" Vector__XXX
 SG_ Cell12 m3 : 32|12@1+ (1,405) [405|4500] "" Vector__XXX
 SG_ CellTemp3 m6 : 24|8@1+ (1,-40) [-40|140] "" Vector__XXX
 SG_ Cell8 m2 : 20|12@1+ (1,405) [405|4500] "" Vector__XXX
 SG_ Cell5 m1 : 20|12@1+ (1,405) [405|4500] "" Vector__XXX
 SG_ Cell2 m0 : 20|12@1+ (1,405) [405|4500] "" Vector__XXX
 SG_ Cell17 m5 : 20|12@1+ (1,405) [405|4500] "" Vector__XXX
 SG_ Cell14 m4 : 20|12@1+ (1,405) [405|4500] "" Vector__XXX
 SG_ Cell11 m3 : 20|12@1+ (1,405) [405|4500] "" Vector__XXX
 SG_ CellTemp2 m6 : 16|8@1+ (1,-40) [-40|140] "" Vector__XXX
 SG_ CellTemp1 m6 : 8|8@1+ (1,-40) [-40|140] "" Vector__XXX
 SG_ Cell7 m2 : 8|12@1+ (1,405) [405|4500] "" Vector__XXX
 SG_ Cell4 m1 : 8|12@1+ (1,405) [405|4500] "" Vector__XXX
 SG_ Cell16 m5 : 8|12@1+ (1,405) [405|4500] "" Vector__XXX
 SG_ Cell13 m4 : 8|12@1+ (1,405) [405|4500] "" Vector__XXX
 SG_ Cell10 m3 : 8|12@1+ (1,405) [405|4500] "" Vector__XXX
 SG_ Cell1 m0 : 8|12@1+ (1,405) [405|4500] "" Vector__XXX
 SG_ Cell_Cnt : 4|4@1+ (1,0) [0|15] "" Vector__XXX
 SG_ Cell_Idx M : 0|4@1+ (1,0) [0|4095] "" Vector__XXX

BO_ 1028 BMS_TX_CMD_5: 6 Vector__XXX
 SG_ CellTemp4 m6 : 32|8@1+ (1,-40) [-40|140] "" Vector__XXX
 SG_ Cell9 m2 : 32|12@1+ (1,405) [405|4500] "" Vector__XXX
 SG_ Cell6 m1 : 32|12@1+ (1,405) [405|4500] "" Vector__XXX
 SG_ Cell3 m0 : 32|12@1+ (1,405) [405|4500] "" Vector__XXX
 SG_ Cell18 m5 : 32|12@1+ (1,405) [405|4500] "" Vector__XXX
 SG_ Cell15 m4 : 32|12@1+ (1,405) [405|4500] "" Vector__XXX
 SG_ Cell12 m3 : 32|12@1+ (1,405) [405|4500] "" Vector__XXX
 SG_ CellTemp3 m6 : 24|8@1+ (1,-40) [-40|140] "" Vector__XXX
 SG_ Cell8 m2 : 20|12@1+ (1,405) [405|4500] "" Vector__XXX
 SG_ Cell5 m1 : 20|12@1+ (1,405) [405|4500] "" Vector__XXX
 SG_ Cell2 m0 : 20|12@1+ (1,405) [405|4500] "" Vector__XXX
 SG_ Cell17 m5 : 20|12@1+ (1,405) [405|4500] "" Vector__XXX
 SG_ Cell14 m4 : 20|12@1+ (1,405) [405|4500] "" Vector__XXX
 SG_ Cell11 m3 : 20|12@1+ (1,405) [405|4500] "" Vector__XXX
 SG_ CellTemp2 m6 : 16|8@1+ (1,-40) [-40|140] "" Vector__XXX
 SG_ CellTemp1 m6 : 8|8@1+ (1,-40) [-40|140] "" Vector__XXX
 SG_ Cell7 m2 : 8|12@1+ (1,405) [405|4500] "" Vector__XXX
 SG_ Cell4 m1 : 8|12@1+ (1,405) [405|4500] "" Vector__XXX
 SG_ Cell16 m5 : 8|12@1+ (1,405) [405|4500] "" Vector__XXX
 SG_ Cell13 m4 : 8|12@1+ (1,405) [405|4500] "" Vector__XXX
 SG_ Cell10 m3 : 8|12@1+ (1,405) [405|4500] "" Vector__XXX
 SG_ Cell1 m0 : 8|12@1+ (1,405) [405|4500] "" Vector__XXX
 SG_ Cell_Cnt : 4|4@1+ (1,0) [0|15] "" Vector__XXX
 SG_ Cell_Idx M : 0|4@1+ (1,0) [0|4095] "" Vector__XXX

BO_ 1029 BMS_TX_CMD_6: 6 Vector__XXX
 SG_ CellTemp4 m6 : 32|8@1+ (1,-40) [-40|140] "" Vector__XXX
 SG_ Cell9 m2 : 32|12@1+ (1,405) [405|4500] "" Vector__XXX
 SG_ Cell6 m1 : 32|12@1+ (1,405) [405|4500] "" Vector__XXX
 SG_ Cell3 m0 : 32|12@1+ (1,405) [405|4500] "" Vector__XXX
 SG_ Cell18 m5 : 32|12@1+ (1,405) [405|4500] "" Vector__XXX
 SG_ Cell15 m4 : 32|12@1+ (1,405) [405|4500] "" Vector__XXX
 SG_ Cell12 m3 : 32|12@1+ (1,405) [405|4500] "" Vector__XXX
 SG_ CellTemp3 m6 : 24|8@1+ (1,-40) [-40|140] "" Vector__XXX
 SG_ Cell8 m2 : 20|12@1+ (1,405) [405|4500] "" Vector__XXX
 SG_ Cell5 m1 : 20|12@1+ (1,405) [405|4500] "" Vector__XXX
 SG_ Cell2 m0 : 20|12@1+ (1,405) [405|4500] "" Vector__XXX
 SG_ Cell17 m5 : 20|12@1+ (1,405) [405|4500] "" Vector__XXX
 SG_ Cell14 m4 : 20|12@1+ (1,405) [405|4500] "" Vector__XXX
 SG_ Cell11 m3 : 20|12@1+ (1,405) [405|4500] "" Vector__XXX
 SG_ CellTemp2 m6 : 16|8@1+ (1,-40) [-40|140] "" Vector__XXX
 SG_ CellTemp1 m6 : 8|8@1+ (1,-40) [-40|140] "" Vector__XXX
 SG_ Cell7 m2 : 8|12@1+ (1,405) [405|4500] "" Vector__XXX
 SG_ Cell4 m1 : 8|12@1+ (1,405) [405|4500] "" Vector__XXX
 SG_ Cell16 m5 : 8|12@1+ (1,405) [405|4500] "" Vector__XXX
 SG_ Cell13 m4 : 8|12@1+ (1,405) [405|4500] "" Vector__XXX
 SG_ Cell10 m3 : 8|12@1+ (1,405) [405|4500] "" Vector__XXX
 SG_ Cell1 m0 : 8|12@1+ (1,405) [405|4500] "" Vector__XXX
 SG_ Cell_Cnt : 4|4@1+ (1,0) [0|15] "" Vector__XXX
 SG_ Cell_Idx M : 0|4@1+ (1,0) [0|4095] "" Vector__XXX

BO_ 1030 BMS_TX_CMD_7: 6 Vector__XXX
 SG_ CellTemp4 m6 : 32|8@1+ (1,-40) [-40|140] "" Vector__XXX
 SG_ Cell9 m2 : 32|12@1+ (1,405) [405|4500] "" Vector__XXX
 SG_ Cell6 m1 : 32|12@1+ (1,405) [405|4500] "" Vector__XXX
 SG_ Cell3 m0 : 32|12@1+ (1,405) [405|4500] "" Vector__XXX
 SG_ Cell18 m5 : 32|12@1+ (1,405) [405|4500] "" Vector__XXX
 SG_ Cell15 m4 : 32|12@1+ (1,405) [405|4500] "" Vector__XXX
 SG_ Cell12 m3 : 32|12@1+ (1,405) [405|4500] "" Vector__XXX
 SG_ CellTemp3 m6 : 24|8@1+ (1,-40) [-40|140] "" Vector__XXX
 SG_ Cell8 m2 : 20|12@1+ (1,405) [405|4500] "" Vector__XXX
 SG_ Cell5 m1 : 20|12@1+ (1,405) [405|4500] "" Vector__XXX
 SG_ Cell2 m0 : 20|12@1+ (1,405) [405|4500] "" Vector__XXX
 SG_ Cell17 m5 : 20|12@1+ (1,405) [405|4500] "" Vector__XXX
 SG_ Cell14 m4 : 20|12@1+ (1,405) [405|4500] "" Vector__XXX
 SG_ Cell11 m3 : 20|12@1+ (1,405) [405|4500] "" Vector__XXX
 SG_ CellTemp2 m6 : 16|8@1+ (1,-40) [-40|140] "" Vector__XXX
 SG_ CellTemp1 m6 : 8|8@1+ (1,-40) [-40|140] "" Vector__XXX
 SG_ Cell7 m2 : 8|12@1+ (1,405) [405|4500] "" Vector__XXX
 SG_ Cell4 m1 : 8|12@1+ (1,405) [405|4500] "" Vector__XXX
 SG_ Cell16 m5 : 8|12@1+ (1,405) [405|4500] "" Vector__XXX
 SG_ Cell13 m4 : 8|12@1+ (1,405) [405|4500] "" Vector__XXX
 SG_ Cell10 m3 : 8|12@1+ (1,405) [405|4500] "" Vector__XXX
 SG_ Cell1 m0 : 8|12@1+ (1,405) [405|4500] "" Vector__XXX
 SG_ Cell_Cnt : 4|4@1+ (1,0) [0|15] "" Vector__XXX
 SG_ Cell_Idx M : 0|4@1+ (1,0) [0|4095] "" Vector__XXX

BO_ 1031 BMS_TX_CMD_8: 6 Vector__XXX
 SG_ CellTemp4 m6 : 32|8@1+ (1,-40) [-40|140] "" Vector__XXX
 SG_ Cell9 m2 : 32|12@1+ (1,405) [405|4500] "" Vector__XXX
 SG_ Cell6 m1 : 32|12@1+ (1,405) [405|4500] "" Vector__XXX
 SG_ Cell3 m0 : 32|12@1+ (1,405) [405|4500] "" Vector__XXX
 SG_ Cell18 m5 : 32|12@1+ (1,405) [405|4500] "" Vector__XXX
 SG_ Cell15 m4 : 32|12@1+ (1,405) [405|4500] "" Vector__XXX
 SG_ Cell12 m3 : 32|12@1+ (1,405) [405|4500] "" Vector__XXX
 SG_ CellTemp3 m6 : 24|8@1+ (1,-40) [-40|140] "" Vector__XXX
 SG_ Cell8 m2 : 20|12@1+ (1,405) [405|4500] "" Vector__XXX
 SG_ Cell5 m1 : 20|12@1+ (1,405) [405|4500] "" Vector__XXX
 SG_ Cell2 m0 : 20|12@1+ (1,405) [405|4500] "" Vector__XXX
 SG_ Cell17 m5 : 20|12@1+ (1,405) [405|4500] "" Vector__XXX
 SG_ Cell14 m4 : 20|12@1+ (1,405) [405|4500] "" Vector__XXX
 SG_ Cell11 m3 : 20|12@1+ (1,405) [405|4500] "" Vector__XXX
 SG_ CellTemp2 m6 : 16|8@1+ (1,-40) [-40|140] "" Vector__XXX
 SG_ CellTemp1 m6 : 8|8@1+ (1,-40) [-40|140] "" Vector__XXX
 SG_ Cell7 m2 : 8|12@1+ (1,405) [405|4500] "" Vector__XXX
 SG_ Cell4 m1 : 8|12@1+ (1,405) [405|4500] "" Vector__XXX
 SG_ Cell16 m5 : 8|12@1+ (1,405) [405|4500] "" Vector__XXX
 SG_ Cell13 m4 : 8|12@1+ (1,405) [405|4500] "" Vector__XXX
 SG_ Cell10 m3 : 8|12@1+ (1,405) [405|4500] "" Vector__XXX
 SG_ Cell1 m0 : 8|12@1+ (1,405) [405|4500] "" Vector__XXX
 SG_ Cell_Cnt : 4|4@1+ (1,0) [0|15] "" Vector__XXX
 SG_ Cell_Idx M : 0|4@1+ (1,0) [0|4095] "" Vector__XXX

BO_ 1032 BMS_TX_CMD_9: 6 Vector__XXX
 SG_ CellTemp4 m6 : 32|8@1+ (1,-40) [-40|140] "" Vector__XXX
 SG_ Cell9 m2 : 32|12@1+ (1,405) [405|4500] "" Vector__XXX
 SG_ Cell6 m1 : 32|12@1+ (1,405) [405|4500] "" Vector__XXX
 SG_ Cell3 m0 : 32|12@1+ (1,405) [405|4500] "" Vector__XXX
 SG_ Cell18 m5 : 32|12@1+ (1,405) [405|4500] "" Vector__XXX
 SG_ Cell15 m4 : 32|12@1+ (1,405) [405|4500] "" Vector__XXX
 SG_ Cell12 m3 : 32|12@1+ (1,405) [405|4500] "" Vector__XXX
 SG_ CellTemp3 m6 : 24|8@1+ (1,-40) [-40|140] "" Vector__XXX
 SG_ Cell8 m2 : 20|12@1+ (1,405) [405|4500] "" Vector__XXX
 SG_ Cell5 m1 : 20|12@1+ (1,405) [405|4500] "" Vector__XXX
 SG_ Cell2 m0 : 20|12@1+ (1,405) [405|4500] "" Vector__XXX
 SG_ Cell17 m5 : 20|12@1+ (1,405) [405|4500] "" Vector__XXX
 SG_ Cell14 m4 : 20|12@1+ (1,405) [405|4500] "" Vector__XXX
 SG_ Cell11 m3 : 20|12@1+ (1,405) [405|4500] "" Vector__XXX
 SG_ CellTemp2 m6 : 16|8@1+ (1,-40) [-40|140] "" Vector__XXX
 SG_ CellTemp1 m6 : 8|8@1+ (1,-40) [-40|140] "" Vector__XXX
 SG_ Cell7 m2 : 8|12@1+ (1,405) [405|4500] "" Vector__XXX
 SG_ Cell4 m1 : 8|12@1+ (1,405) [405|4500] "" Vector__XXX
 SG_ Cell16 m5 : 8|12@1+ (1,405) [405|4500] "" Vector__XXX
 SG_ Cell13 m4 : 8|12@1+ (1,405) [405|4500] "" Vector__XXX
 SG_ Cell10 m3 : 8|12@1+ (1,405) [405|4500] "" Vector__XXX
 SG_ Cell1 m0 : 8|12@1+ (1,405) [405|4500] "" Vector__XXX
 SG_ Cell_Cnt : 4|4@1+ (1,0) [0|15] "" Vector__XXX
 SG_ Cell_Idx M : 0|4@1+ (1,0) [0|4095] "" Vector__XXX

BO_ 1033 BMS_TX_CMD_10: 6 Vector__XXX
 SG_ CellTemp4 m6 : 32|8@1+ (1,-40) [-40|140] "" Vector__XXX
 SG_ Cell9 m2 : 32|12@1+ (1,405) [405|4500] "" Vector__XXX
 SG_ Cell6 m1 : 32|12@1+ (1,405) [405|4500] "" Vector__XXX
 SG_ Cell3 m0 : 32|12@1+ (1,405) [405|4500] "" Vector__XXX
 SG_ Cell18 m5 : 32|12@1+ (1,405) [405|4500] "" Vector__XXX
 SG_ Cell15 m4 : 32|12@1+ (1,405) [405|4500] "" Vector__XXX
 SG_ Cell12 m3 : 32|12@1+ (1,405) [405|4500] "" Vector__XXX
 SG_ CellTemp3 m6 : 24|8@1+ (1,-40) [-40|140] "" Vector__XXX
 SG_ Cell8 m2 : 20|12@1+ (1,405) [405|4500] "" Vector__XXX
 SG_ Cell5 m1 : 20|12@1+ (1,405) [405|4500] "" Vector__XXX
 SG_ Cell2 m0 : 20|12@1+ (1,405) [405|4500] "" Vector__XXX
 SG_ Cell17 m5 : 20|12@1+ (1,405) [405|4500] "" Vector__XXX
 SG_ Cell14 m4 : 20|12@1+ (1,405) [405|4500] "" Vector__XXX
 SG_ Cell11 m3 : 20|12@1+ (1,405) [405|4500] "" Vector__XXX
 SG_ CellTemp2 m6 : 16|8@1+ (1,-40) [-40|140] "" Vector__XXX
 SG_ CellTemp1 m6 : 8|8@1+ (1,-40) [-40|140] "" Vector__XXX
 SG_ Cell7 m2 : 8|12@1+ (1,405) [405|4500] "" Vector__XXX
 SG_ Cell4 m1 : 8|12@1+ (1,405) [405|4500] "" Vector__XXX
 SG_ Cell16 m5 : 8|12@1+ (1,405) [405|4500] "" Vector__XXX
 SG_ Cell13 m4 : 8|12@1+ (1,405) [405|4500] "" Vector__XXX
 SG_ Cell10 m3 : 8|12@1+ (1,405) [405|4500] "" Vector__XXX
 SG_ Cell1 m0 : 8|12@1+ (1,405) [405|4500] "" Vector__XXX
 SG_ Cell_Cnt : 4|4@1+ (1,0) [0|15] "" Vector__XXX
 SG_ Cell_Idx M : 0|4@1+ (1,0) [0|4095] "" Vector__XXX

BO_ 1034 BMS_TX_CMD_11: 6 Vector__XXX
 SG_ CellTemp4 m6 : 32|8@1+ (1,-40) [-40|140] "" Vector__XXX
 SG_ Cell9 m2 : 32|12@1+ (1,405) [405|4500] "" Vector__XXX
 SG_ Cell6 m1 : 32|12@1+ (1,405) [405|4500] "" Vector__XXX
 SG_ Cell3 m0 : 32|12@1+ (1,405) [405|4500] "" Vector__XXX
 SG_ Cell18 m5 : 32|12@1+ (1,405) [405|4500] "" Vector__XXX
 SG_ Cell15 m4 : 32|12@1+ (1,405) [405|4500] "" Vector__XXX
 SG_ Cell12 m3 : 32|12@1+ (1,405) [405|4500] "" Vector__XXX
 SG_ CellTemp3 m6 : 24|8@1+ (1,-40) [-40|140] "" Vector__XXX
 SG_ Cell8 m2 : 20|12@1+ (1,405) [405|4500] "" Vector__XXX
 SG_ Cell5 m1 : 20|12@1+ (1,405) [405|4500] "" Vector__XXX
 SG_ Cell2 m0 : 20|12@1+ (1,405) [405|4500] "" Vector__XXX
 SG_ Cell17 m5 : 20|12@1+ (1,405) [405|4500] "" Vector__XXX
 SG_ Cell14 m4 : 20|12@1+ (1,405) [405|4500] "" Vector__XXX
 SG_ Cell11 m3 : 20|12@1+ (1,405) [405|4500] "" Vector__XXX
 SG_ CellTemp2 m6 : 16|8@1+ (1,-40) [-40|140] "" Vector__XXX
 SG_ CellTemp1 m6 : 8|8@1+ (1,-40) [-40|140] "" Vector__XXX
 SG_ Cell7 m2 : 8|12@1+ (1,405) [405|4500] "" Vector__XXX
 SG_ Cell4 m1 : 8|12@1+ (1,405) [405|4500] "" Vector__XXX
 SG_ Cell16 m5 : 8|12@1+ (1,405) [405|4500] "" Vector__XXX
 SG_ Cell13 m4 : 8|12@1+ (1,405) [405|4500] "" Vector__XXX
 SG_ Cell10 m3 : 8|12@1+ (1,405) [405|4500] "" Vector__XXX
 SG_ Cell1 m0 : 8|12@1+ (1,405) [405|4500] "" Vector__XXX
 SG_ Cell_Cnt : 4|4@1+ (1,0) [0|15] "" Vector__XXX
 SG_ Cell_Idx M : 0|4@1+ (1,0) [0|4095] "" Vector__XXX

BO_ 1035 BMS_TX_CMD_12: 6 Vector__XXX
 SG_ CellTemp4 m6 : 32|8@1+ (1,-40) [-40|140] "" Vector__XXX
 SG_ Cell9 m2 : 32|12@1+ (1,405) [405|4500] "" Vector__XXX
 SG_ Cell6 m1 : 32|12@1+ (1,405) [405|4500] "" Vector__XXX
 SG_ Cell3 m0 : 32|12@1+ (1,405) [405|4500] "" Vector__XXX
 SG_ Cell18 m5 : 32|12@1+ (1,405) [405|4500] "" Vector__XXX
 SG_ Cell15 m4 : 32|12@1+ (1,405) [405|4500] "" Vector__XXX
 SG_ Cell12 m3 : 32|12@1+ (1,405) [405|4500] "" Vector__XXX
 SG_ CellTemp3 m6 : 24|8@1+ (1,-40) [-40|140] "" Vector__XXX
 SG_ Cell8 m2 : 20|12@1+ (1,405) [405|4500] "" Vector__XXX
 SG_ Cell5 m1 : 20|12@1+ (1,405) [405|4500] "" Vector__XXX
 SG_ Cell2 m0 : 20|12@1+ (1,405) [405|4500] "" Vector__XXX
 SG_ Cell17 m5 : 20|12@1+ (1,405) [405|4500] "" Vector__XXX
 SG_ Cell14 m4 : 20|12@1+ (1,405) [405|4500] "" Vector__XXX
 SG_ Cell11 m3 : 20|12@1+ (1,405) [405|4500] "" Vector__XXX
 SG_ CellTemp2 m6 : 16|8@1+ (1,-40) [-40|140] "" Vector__XXX
 SG_ CellTemp1 m6 : 8|8@1+ (1,-40) [-40|140] "" Vector__XXX
 SG_ Cell7 m2 : 8|12@1+ (1,405) [405|4500] "" Vector__XXX
 SG_ Cell4 m1 : 8|12@1+ (1,405) [405|4500] "" Vector__XXX
 SG_ Cell16 m5 : 8|12@1+ (1,405) [405|4500] "" Vector__XXX
 SG_ Cell13 m4 : 8|12@1+ (1,405) [405|4500] "" Vector__XXX
 SG_ Cell10 m3 : 8|12@1+ (1,405) [405|4500] "" Vector__XXX
 SG_ Cell1 m0 : 8|12@1+ (1,405) [405|4500] "" Vector__XXX
 SG_ Cell_Cnt : 4|4@1+ (1,0) [0|15] "" Vector__XXX
 SG_ Cell_Idx M : 0|4@1+ (1,0) [0|4095] "" Vector__XXX

BO_ 1036 BMS_TX_CMD_13: 6 Vector__XXX
 SG_ CellTemp4 m6 : 32|8@1+ (1,-40) [-40|140] "" Vector__XXX
 SG_ Cell9 m2 : 32|12@1+ (1,405) [405|4500] "" Vector__XXX
 SG_ Cell6 m1 : 32|12@1+ (1,405) [405|4500] "" Vector__XXX
 SG_ Cell3 m0 : 32|12@1+ (1,405) [405|4500] "" Vector__XXX
 SG_ Cell18 m5 : 32|12@1+ (1,405) [405|4500] "" Vector__XXX
 SG_ Cell15 m4 : 32|12@1+ (1,405) [405|4500] "" Vector__XXX
 SG_ Cell12 m3 : 32|12@1+ (1,405) [405|4500] "" Vector__XXX
 SG_ CellTemp3 m6 : 24|8@1+ (1,-40) [-40|140] "" Vector__XXX
 SG_ Cell8 m2 : 20|12@1+ (1,405) [405|4500] "" Vector__XXX
 SG_ Cell5 m1 : 20|12@1+ (1,405) [405|4500] "" Vector__XXX
 SG_ Cell2 m0 : 20|12@1+ (1,405) [405|4500] "" Vector__XXX
 SG_ Cell17 m5 : 20|12@1+ (1,405) [405|4500] "" Vector__XXX
 SG_ Cell14 m4 : 20|12@1+ (1,405) [405|4500] "" Vector__XXX
 SG_ Cell11 m3 : 20|12@1+ (1,405) [405|4500] "" Vector__XXX
 SG_ CellTemp2 m6 : 16|8@1+ (1,-40) [-40|140] "" Vector__XXX
 SG_ CellTemp1 m6 : 8|8@1+ (1,-40) [-40|140] "" Vector__XXX
 SG_ Cell7 m2 : 8|12@1+ (1,405) [405|4500] "" Vector__XXX
 SG_ Cell4 m1 : 8|12@1+ (1,405) [405|4500] "" Vector__XXX
 SG_ Cell16 m5 : 8|12@1+ (1,405) [405|4500] "" Vector__XXX
 SG_ Cell13 m4 : 8|12@1+ (1,405) [405|4500] "" Vector__XXX
 SG_ Cell10 m3 : 8|12@1+ (1,405) [405|4500] "" Vector__XXX
 SG_ Cell1 m0 : 8|12@1+ (1,405) [405|4500] "" Vector__XXX
 SG_ Cell_Cnt : 4|4@1+ (1,0) [0|15] "" Vector__XXX
 SG_ Cell_Idx M : 0|4@1+ (1,0) [0|4095] "" Vector__XXX

BO_ 1037 BMS_TX_CMD_14: 6 Vector__XXX
 SG_ CellTemp4 m6 : 32|8@1+ (1,-40) [-40|140] "" Vector__XXX
 SG_ Cell9 m2 : 32|12@1+ (1,405) [405|4500] "" Vector__XXX
 SG_ Cell6 m1 : 32|12@1+ (1,405) [405|4500] "" Vector__XXX
 SG_ Cell3 m0 : 32|12@1+ (1,405) [405|4500] "" Vector__XXX
 SG_ Cell18 m5 : 32|12@1+ (1,405) [405|4500] "" Vector__XXX
 SG_ Cell15 m4 : 32|12@1+ (1,405) [405|4500] "" Vector__XXX
 SG_ Cell12 m3 : 32|12@1+ (1,405) [405|4500] "" Vector__XXX
 SG_ CellTemp3 m6 : 24|8@1+ (1,-40) [-40|140] "" Vector__XXX
 SG_ Cell8 m2 : 20|12@1+ (1,405) [405|4500] "" Vector__XXX
 SG_ Cell5 m1 : 20|12@1+ (1,405) [405|4500] "" Vector__XXX
 SG_ Cell2 m0 : 20|12@1+ (1,405) [405|4500] "" Vector__XXX
 SG_ Cell17 m5 : 20|12@1+ (1,405) [405|4500] "" Vector__XXX
 SG_ Cell14 m4 : 20|12@1+ (1,405) [405|4500] "" Vector__XXX
 SG_ Cell11 m3 : 20|12@1+ (1,405) [405|4500] "" Vector__XXX
 SG_ CellTemp2 m6 : 16|8@1+ (1,-40) [-40|140] "" Vector__XXX
 SG_ CellTemp1 m6 : 8|8@1+ (1,-40) [-40|140] "" Vector__XXX
 SG_ Cell7 m2 : 8|12@1+ (1,405) [405|4500] "" Vector__XXX
 SG_ Cell4 m1 : 8|12@1+ (1,405) [405|4500] "" Vector__XXX
 SG_ Cell16 m5 : 8|12@1+ (1,405) [405|4500] "" Vector__XXX
 SG_ Cell13 m4 : 8|12@1+ (1,405) [405|4500] "" Vector__XXX
 SG_ Cell10 m3 : 8|12@1+ (1,405) [405|4500] "" Vector__XXX
 SG_ Cell1 m0 : 8|12@1+ (1,405) [405|4500] "" Vector__XXX
 SG_ Cell_Cnt : 4|4@1+ (1,0) [0|15] "" Vector__XXX
 SG_ Cell_Idx M : 0|4@1+ (1,0) [0|4095] "" Vector__XXX

BO_ 1038 BMS_TX_CMD_15: 6 Vector__XXX
 SG_ CellTemp4 m6 : 32|8@1+ (1,-40) [-40|140] "" Vector__XXX
 SG_ Cell9 m2 : 32|12@1+ (1,405) [405|4500] "" Vector__XXX
 SG_ Cell6 m1 : 32|12@1+ (1,405) [405|4500] "" Vector__XXX
 SG_ Cell3 m0 : 32|12@1+ (1,405) [405|4500] "" Vector__XXX
 SG_ Cell18 m5 : 32|12@1+ (1,405) [405|4500] "" Vector__XXX
 SG_ Cell15 m4 : 32|12@1+ (1,405) [405|4500] "" Vector__XXX
 SG_ Cell12 m3 : 32|12@1+ (1,405) [405|4500] "" Vector__XXX
 SG_ CellTemp3 m6 : 24|8@1+ (1,-40) [-40|140] "" Vector__XXX
 SG_ Cell8 m2 : 20|12@1+ (1,405) [405|4500] "" Vector__XXX
 SG_ Cell5 m1 : 20|12@1+ (1,405) [405|4500] "" Vector__XXX
 SG_ Cell2 m0 : 20|12@1+ (1,405) [405|4500] "" Vector__XXX
 SG_ Cell17 m5 : 20|12@1+ (1,405) [405|4500] "" Vector__XXX
 SG_ Cell14 m4 : 20|12@1+ (1,405) [405|4500] "" Vector__XXX
 SG_ Cell11 m3 : 20|12@1+ (1,405) [405|4500] "" Vector__XXX
 SG_ CellTemp2 m6 : 16|8@1+ (1,-40) [-40|140] "" Vector__XXX
 SG_ CellTemp1 m6 : 8|8@1+ (1,-40) [-40|140] "" Vector__XXX
 SG_ Cell7 m2 : 8|12@1+ (1,405) [405|4500] "" Vector__XXX
 SG_ Cell4 m1 : 8|12@1+ (1,405) [405|4500] "" Vector__XXX
 SG_ Cell16 m5 : 8|12@1+ (1,405) [405|4500] "" Vector__XXX
 SG_ Cell13 m4 : 8|12@1+ (1,405) [405|4500] "" Vector__XXX
 SG_ Cell10 m3 : 8|12@1+ (1,405) [405|4500] "" Vector__XXX
 SG_ Cell1 m0 : 8|12@1+ (1,405) [405|4500] "" Vector__XXX
 SG_ Cell_Cnt : 4|4@1+ (1,0) [0|15] "" Vector__XXX
 SG_ Cell_Idx M : 0|4@1+ (1,0) [0|4095] "" Vector__XXX

BO_ 1039 BMS_TX_CMD_16: 6 Vector__XXX
 SG_ CellTemp4 m6 : 32|8@1+ (1,-40) [-40|140] "" Vector__XXX
 SG_ Cell9 m2 : 32|12@1+ (1,405) [405|4500] "" Vector__XXX
 SG_ Cell6 m1 : 32|12@1+ (1,405) [405|4500] "" Vector__XXX
 SG_ Cell3 m0 : 32|12@1+ (1,405) [405|4500] "" Vector__XXX
 SG_ Cell18 m5 : 32|12@1+ (1,405) [405|4500] "" Vector__XXX
 SG_ Cell15 m4 : 32|12@1+ (1,405) [405|4500] "" Vector__XXX
 SG_ Cell12 m3 : 32|12@1+ (1,405) [405|4500] "" Vector__XXX
 SG_ CellTemp3 m6 : 24|8@1+ (1,-40) [-40|140] "" Vector__XXX
 SG_ Cell8 m2 : 20|12@1+ (1,405) [405|4500] "" Vector__XXX
 SG_ Cell5 m1 : 20|12@1+ (1,405) [405|4500] "" Vector__XXX
 SG_ Cell2 m0 : 20|12@1+ (1,405) [405|4500] "" Vector__XXX
 SG_ Cell17 m5 : 20|12@1+ (1,405) [405|4500] "" Vector__XXX
 SG_ Cell14 m4 : 20|12@1+ (1,405) [405|4500] "" Vector__XXX
 SG_ Cell11 m3 : 20|12@1+ (1,405) [405|4500] "" Vector__XXX
 SG_ CellTemp2 m6 : 16|8@1+ (1,-40) [-40|140] "" Vector__XXX
 SG_ CellTemp1 m6 : 8|8@1+ (1,-40) [-40|140] "" Vector__XXX
 SG_ Cell7 m2 : 8|12@1+ (1,405) [405|4500] "" Vector__XXX
 SG_ Cell4 m1 : 8|12@1+ (1,405) [405|4500] "" Vector__XXX
 SG_ Cell16 m5 : 8|12@1+ (1,405) [405|4500] "" Vector__XXX
 SG_ Cell13 m4 : 8|12@1+ (1,405) [405|4500] "" Vector__XXX
 SG_ Cell10 m3 : 8|12@1+ (1,405) [405|4500] "" Vector__XXX
 SG_ Cell1 m0 : 8|12@1+ (1,405) [405|4500] "" Vector__XXX
 SG_ Cell_Cnt : 4|4@1+ (1,0) [0|15] "" Vector__XXX
 SG_ Cell_Idx M : 0|4@1+ (1,0) [0|4095] "" Vector__XXX

BO_ 1040 BMS_TX_CMD_17: 6 Vector__XXX
 SG_ CellTemp4 m6 : 32|8@1+ (1,-40) [-40|140] "" Vector__XXX
 SG_ Cell9 m2 : 32|12@1+ (1,405) [405|4500] "" Vector__XXX
 SG_ Cell6 m1 : 32|12@1+ (1,405) [405|4500] "" Vector__XXX
 SG_ Cell3 m0 : 32|12@1+ (1,405) [405|4500] "" Vector__XXX
 SG_ Cell18 m5 : 32|12@1+ (1,405) [405|4500] "" Vector__XXX
 SG_ Cell15 m4 : 32|12@1+ (1,405) [405|4500] "" Vector__XXX
 SG_ Cell12 m3 : 32|12@1+ (1,405) [405|4500] "" Vector__XXX
 SG_ CellTemp3 m6 : 24|8@1+ (1,-40) [-40|140] "" Vector__XXX
 SG_ Cell8 m2 : 20|12@1+ (1,405) [405|4500] "" Vector__XXX
 SG_ Cell5 m1 : 20|12@1+ (1,405) [405|4500] "" Vector__XXX
 SG_ Cell2 m0 : 20|12@1+ (1,405) [405|4500] "" Vector__XXX
 SG_ Cell17 m5 : 20|12@1+ (1,405) [405|4500] "" Vector__XXX
 SG_ Cell14 m4 : 20|12@1+ (1,405) [405|4500] "" Vector__XXX
 SG_ Cell11 m3 : 20|12@1+ (1,405) [405|4500] "" Vector__XXX
 SG_ CellTemp2 m6 : 16|8@1+ (1,-40) [-40|140] "" Vector__XXX
 SG_ CellTemp1 m6 : 8|8@1+ (1,-40) [-40|140] "" Vector__XXX
 SG_ Cell7 m2 : 8|12@1+ (1,405) [405|4500] "" Vector__XXX
 SG_ Cell4 m1 : 8|12@1+ (1,405) [405|4500] "" Vector__XXX
 SG_ Cell16 m5 : 8|12@1+ (1,405) [405|4500] "" Vector__XXX
 SG_ Cell13 m4 : 8|12@1+ (1,405) [405|4500] "" Vector__XXX
 SG_ Cell10 m3 : 8|12@1+ (1,405) [405|4500] "" Vector__XXX
 SG_ Cell1 m0 : 8|12@1+ (1,405) [405|4500] "" Vector__XXX
 SG_ Cell_Cnt : 4|4@1+ (1,0) [0|15] "" Vector__XXX
 SG_ Cell_Idx M : 0|4@1+ (1,0) [0|4095] "" Vector__XXX

BO_ 1041 BMS_TX_CMD_18: 6 Vector__XXX
 SG_ CellTemp4 m6 : 32|8@1+ (1,-40) [-40|140] "" Vector__XXX
 SG_ Cell9 m2 : 32|12@1+ (1,405) [405|4500] "" Vector__XXX
 SG_ Cell6 m1 : 32|12@1+ (1,405) [405|4500] "" Vector__XXX
 SG_ Cell3 m0 : 32|12@1+ (1,405) [405|4500] "" Vector__XXX
 SG_ Cell18 m5 : 32|12@1+ (1,405) [405|4500] "" Vector__XXX
 SG_ Cell15 m4 : 32|12@1+ (1,405) [405|4500] "" Vector__XXX
 SG_ Cell12 m3 : 32|12@1+ (1,405) [405|4500] "" Vector__XXX
 SG_ CellTemp3 m6 : 24|8@1+ (1,-40) [-40|140] "" Vector__XXX
 SG_ Cell8 m2 : 20|12@1+ (1,405) [405|4500] "" Vector__XXX
 SG_ Cell5 m1 : 20|12@1+ (1,405) [405|4500] "" Vector__XXX
 SG_ Cell2 m0 : 20|12@1+ (1,405) [405|4500] "" Vector__XXX
 SG_ Cell17 m5 : 20|12@1+ (1,405) [405|4500] "" Vector__XXX
 SG_ Cell14 m4 : 20|12@1+ (1,405) [405|4500] "" Vector__XXX
 SG_ Cell11 m3 : 20|12@1+ (1,405) [405|4500] "" Vector__XXX
 SG_ CellTemp2 m6 : 16|8@1+ (1,-40) [-40|140] "" Vector__XXX
 SG_ CellTemp1 m6 : 8|8@1+ (1,-40) [-40|140] "" Vector__XXX
 SG_ Cell7 m2 : 8|12@1+ (1,405) [405|4500] "" Vector__XXX
 SG_ Cell4 m1 : 8|12@1+ (1,405) [405|4500] "" Vector__XXX
 SG_ Cell16 m5 : 8|12@1+ (1,405) [405|4500] "" Vector__XXX
 SG_ Cell13 m4 : 8|12@1+ (1,405) [405|4500] "" Vector__XXX
 SG_ Cell10 m3 : 8|12@1+ (1,405) [405|4500] "" Vector__XXX
 SG_ Cell1 m0 : 8|12@1+ (1,405) [405|4500] "" Vector__XXX
 SG_ Cell_Cnt : 4|4@1+ (1,0) [0|15] "" Vector__XXX
 SG_ Cell_Idx M : 0|4@1+ (1,0) [0|4095] "" Vector__XXX

BO_ 1042 BMS_TX_CMD_19: 6 Vector__XXX
 SG_ CellTemp4 m6 : 32|8@1+ (1,-40) [-40|140] "" Vector__XXX
 SG_ Cell9 m2 : 32|12@1+ (1,405) [405|4500] "" Vector__XXX
 SG_ Cell6 m1 : 32|12@1+ (1,405) [405|4500] "" Vector__XXX
 SG_ Cell3 m0 : 32|12@1+ (1,405) [405|4500] "" Vector__XXX
 SG_ Cell18 m5 : 32|12@1+ (1,405) [405|4500] "" Vector__XXX
 SG_ Cell15 m4 : 32|12@1+ (1,405) [405|4500] "" Vector__XXX
 SG_ Cell12 m3 : 32|12@1+ (1,405) [405|4500] "" Vector__XXX
 SG_ CellTemp3 m6 : 24|8@1+ (1,-40) [-40|140] "" Vector__XXX
 SG_ Cell8 m2 : 20|12@1+ (1,405) [405|4500] "" Vector__XXX
 SG_ Cell5 m1 : 20|12@1+ (1,405) [405|4500] "" Vector__XXX
 SG_ Cell2 m0 : 20|12@1+ (1,405) [405|4500] "" Vector__XXX
 SG_ Cell17 m5 : 20|12@1+ (1,405) [405|4500] "" Vector__XXX
 SG_ Cell14 m4 : 20|12@1+ (1,405) [405|4500] "" Vector__XXX
 SG_ Cell11 m3 : 20|12@1+ (1,405) [405|4500] "" Vector__XXX
 SG_ CellTemp2 m6 : 16|8@1+ (1,-40) [-40|140] "" Vector__XXX
 SG_ CellTemp1 m6 : 8|8@1+ (1,-40) [-40|140] "" Vector__XXX
 SG_ Cell7 m2 : 8|12@1+ (1,405) [405|4500] "" Vector__XXX
 SG_ Cell4 m1 : 8|12@1+ (1,405) [405|4500] "" Vector__XXX
 SG_ Cell16 m5 : 8|12@1+ (1,405) [405|4500] "" Vector__XXX
 SG_ Cell13 m4 : 8|12@1+ (1,405) [405|4500] "" Vector__XXX
 SG_ Cell10 m3 : 8|12@1+ (1,405) [405|4500] "" Vector__XXX
 SG_ Cell1 m0 : 8|12@1+ (1,405) [405|4500] "" Vector__XXX
 SG_ Cell_Cnt : 4|4@1+ (1,0) [0|15] "" Vector__XXX
 SG_ Cell_Idx M : 0|4@1+ (1,0) [0|4095] "" Vector__XXX

BO_ 1043 BMS_TX_CMD_20: 6 Vector__XXX
 SG_ CellTemp4 m6 : 32|8@1+ (1,-40) [-40|140] "" Vector__XXX
 SG_ Cell9 m2 : 32|12@1+ (1,405) [405|4500] "" Vector__XXX
 SG_ Cell6 m1 : 32|12@1+ (1,405) [405|4500] "" Vector__XXX
 SG_ Cell3 m0 : 32|12@1+ (1,405) [405|4500] "" Vector__XXX
 SG_ Cell18 m5 : 32|12@1+ (1,405) [405|4500] "" Vector__XXX
 SG_ Cell15 m4 : 32|12@1+ (1,405) [405|4500] "" Vector__XXX
 SG_ Cell12 m3 : 32|12@1+ (1,405) [405|4500] "" Vector__XXX
 SG_ CellTemp3 m6 : 24|8@1+ (1,-40) [-40|140] "" Vector__XXX
 SG_ Cell8 m2 : 20|12@1+ (1,405) [405|4500] "" Vector__XXX
 SG_ Cell5 m1 : 20|12@1+ (1,405) [405|4500] "" Vector__XXX
 SG_ Cell2 m0 : 20|12@1+ (1,405) [405|4500] "" Vector__XXX
 SG_ Cell17 m5 : 20|12@1+ (1,405) [405|4500] "" Vector__XXX
 SG_ Cell14 m4 : 20|12@1+ (1,405) [405|4500] "" Vector__XXX
 SG_ Cell11 m3 : 20|12@1+ (1,405) [405|4500] "" Vector__XXX
 SG_ CellTemp2 m6 : 16|8@1+ (1,-40) [-40|140] "" Vector__XXX
 SG_ CellTemp1 m6 : 8|8@1+ (1,-40) [-40|140] "" Vector__XXX
 SG_ Cell7 m2 : 8|12@1+ (1,405) [405|4500] "" Vector__XXX
 SG_ Cell4 m1 : 8|12@1+ (1,405) [405|4500] "" Vector__XXX
 SG_ Cell16 m5 : 8|12@1+ (1,405) [405|4500] "" Vector__XXX
 SG_ Cell13 m4 : 8|12@1+ (1,405) [405|4500] "" Vector__XXX
 SG_ Cell10 m3 : 8|12@1+ (1,405) [405|4500] "" Vector__XXX
 SG_ Cell1 m0 : 8|12@1+ (1,405) [405|4500] "" Vector__XXX
 SG_ Cell_Cnt : 4|4@1+ (1,0) [0|15] "" Vector__XXX
 SG_ Cell_Idx M : 0|4@1+ (1,0) [0|4095] "" Vector__XXX

BO_ 1044 BMS_TX_CMD_21: 6 Vector__XXX
 SG_ CellTemp4 m6 : 32|8@1+ (1,-40) [-40|140] "" Vector__XXX
 SG_ Cell9 m2 : 32|12@1+ (1,405) [405|4500] "" Vector__XXX
 SG_ Cell6 m1 : 32|12@1+ (1,405) [405|4500] "" Vector__XXX
 SG_ Cell3 m0 : 32|12@1+ (1,405) [405|4500] "" Vector__XXX
 SG_ Cell18 m5 : 32|12@1+ (1,405) [405|4500] "" Vector__XXX
 SG_ Cell15 m4 : 32|12@1+ (1,405) [405|4500] "" Vector__XXX
 SG_ Cell12 m3 : 32|12@1+ (1,405) [405|4500] "" Vector__XXX
 SG_ CellTemp3 m6 : 24|8@1+ (1,-40) [-40|140] "" Vector__XXX
 SG_ Cell8 m2 : 20|12@1+ (1,405) [405|4500] "" Vector__XXX
 SG_ Cell5 m1 : 20|12@1+ (1,405) [405|4500] "" Vector__XXX
 SG_ Cell2 m0 : 20|12@1+ (1,405) [405|4500] "" Vector__XXX
 SG_ Cell17 m5 : 20|12@1+ (1,405) [405|4500] "" Vector__XXX
 SG_ Cell14 m4 : 20|12@1+ (1,405) [405|4500] "" Vector__XXX
 SG_ Cell11 m3 : 20|12@1+ (1,405) [405|4500] "" Vector__XXX
 SG_ CellTemp2 m6 : 16|8@1+ (1,-40) [-40|140] "" Vector__XXX
 SG_ CellTemp1 m6 : 8|8@1+ (1,-40) [-40|140] "" Vector__XXX
 SG_ Cell7 m2 : 8|12@1+ (1,405) [405|4500] "" Vector__XXX
 SG_ Cell4 m1 : 8|12@1+ (1,405) [405|4500] "" Vector__XXX
 SG_ Cell16 m5 : 8|12@1+ (1,405) [405|4500] "" Vector__XXX
 SG_ Cell13 m4 : 8|12@1+ (1,405) [405|4500] "" Vector__XXX
 SG_ Cell10 m3 : 8|12@1+ (1,405) [405|4500] "" Vector__XXX
 SG_ Cell1 m0 : 8|12@1+ (1,405) [405|4500] "" Vector__XXX
 SG_ Cell_Cnt : 4|4@1+ (1,0) [0|15] "" Vector__XXX
 SG_ Cell_Idx M : 0|4@1+ (1,0) [0|4095] "" Vector__XXX

BO_ 1045 BMS_TX_CMD_22: 6 Vector__XXX
 SG_ CellTemp4 m6 : 32|8@1+ (1,-40) [-40|140] "" Vector__XXX
 SG_ Cell9 m2 : 32|12@1+ (1,405) [405|4500] "" Vector__XXX
 SG_ Cell6 m1 : 32|12@1+ (1,405) [405|4500] "" Vector__XXX
 SG_ Cell3 m0 : 32|12@1+ (1,405) [405|4500] "" Vector__XXX
 SG_ Cell18 m5 : 32|12@1+ (1,405) [405|4500] "" Vector__XXX
 SG_ Cell15 m4 : 32|12@1+ (1,405) [405|4500] "" Vector__XXX
 SG_ Cell12 m3 : 32|12@1+ (1,405) [405|4500] "" Vector__XXX
 SG_ CellTemp3 m6 : 24|8@1+ (1,-40) [-40|140] "" Vector__XXX
 SG_ Cell8 m2 : 20|12@1+ (1,405) [405|4500] "" Vector__XXX
 SG_ Cell5 m1 : 20|12@1+ (1,405) [405|4500] "" Vector__XXX
 SG_ Cell2 m0 : 20|12@1+ (1,405) [405|4500] "" Vector__XXX
 SG_ Cell17 m5 : 20|12@1+ (1,405) [405|4500] "" Vector__XXX
 SG_ Cell14 m4 : 20|12@1+ (1,405) [405|4500] "" Vector__XXX
 SG_ Cell11 m3 : 20|12@1+ (1,405) [405|4500] "" Vector__XXX
 SG_ CellTemp2 m6 : 16|8@1+ (1,-40) [-40|140] "" Vector__XXX
 SG_ CellTemp1 m6 : 8|8@1+ (1,-40) [-40|140] "" Vector__XXX
 SG_ Cell7 m2 : 8|12@1+ (1,405) [405|4500] "" Vector__XXX
 SG_ Cell4 m1 : 8|12@1+ (1,405) [405|4500] "" Vector__XXX
 SG_ Cell16 m5 : 8|12@1+ (1,405) [405|4500] "" Vector__XXX
 SG_ Cell13 m4 : 8|12@1+ (1,405) [405|4500] "" Vector__XXX
 SG_ Cell10 m3 : 8|12@1+ (1,405) [405|4500] "" Vector__XXX
 SG_ Cell1 m0 : 8|12@1+ (1,405) [405|4500] "" Vector__XXX
 SG_ Cell_Cnt : 4|4@1+ (1,0) [0|15] "" Vector__XXX
 SG_ Cell_Idx M : 0|4@1+ (1,0) [0|4095] "" Vector__XXX

BO_ 1046 BMS_TX_CMD_23: 6 Vector__XXX
 SG_ CellTemp4 m6 : 32|8@1+ (1,-40) [-40|140] "" Vector__XXX
 SG_ Cell9 m2 : 32|12@1+ (1,405) [405|4500] "" Vector__XXX
 SG_ Cell6 m1 : 32|12@1+ (1,405) [405|4500] "" Vector__XXX
 SG_ Cell3 m0 : 32|12@1+ (1,405) [405|4500] "" Vector__XXX
 SG_ Cell18 m5 : 32|12@1+ (1,405) [405|4500] "" Vector__XXX
 SG_ Cell15 m4 : 32|12@1+ (1,405) [405|4500] "" Vector__XXX
 SG_ Cell12 m3 : 32|12@1+ (1,405) [405|4500] "" Vector__XXX
 SG_ CellTemp3 m6 : 24|8@1+ (1,-40) [-40|140] "" Vector__XXX
 SG_ Cell8 m2 : 20|12@1+ (1,405) [405|4500] "" Vector__XXX
 SG_ Cell5 m1 : 20|12@1+ (1,405) [405|4500] "" Vector__XXX
 SG_ Cell2 m0 : 20|12@1+ (1,405) [405|4500] "" Vector__XXX
 SG_ Cell17 m5 : 20|12@1+ (1,405) [405|4500] "" Vector__XXX
 SG_ Cell14 m4 : 20|12@1+ (1,405) [405|4500] "" Vector__XXX
 SG_ Cell11 m3 : 20|12@1+ (1,405) [405|4500] "" Vector__XXX
 SG_ CellTemp2 m6 : 16|8@1+ (1,-40) [-40|140] "" Vector__XXX
 SG_ CellTemp1 m6 : 8|8@1+ (1,-40) [-40|140] "" Vector__XXX
 SG_ Cell7 m2 : 8|12@1+ (1,405) [405|4500] "" Vector__XXX
 SG_ Cell4 m1 : 8|12@1+ (1,405) [405|4500] "" Vector__XXX
 SG_ Cell16 m5 : 8|12@1+ (1,405) [405|4500] "" Vector__XXX
 SG_ Cell13 m4 : 8|12@1+ (1,405) [405|4500] "" Vector__XXX
 SG_ Cell10 m3 : 8|12@1+ (1,405) [405|4500] "" Vector__XXX
 SG_ Cell1 m0 : 8|12@1+ (1,405) [405|4500] "" Vector__XXX
 SG_ Cell_Cnt : 4|4@1+ (1,0) [0|15] "" Vector__XXX
 SG_ Cell_Idx M : 0|4@1+ (1,0) [0|4095] "" Vector__XXX

BO_ 1047 BMS_TX_CMD_24: 6 Vector__XXX
 SG_ CellTemp4 m6 : 32|8@1+ (1,-40) [-40|140] "" Vector__XXX
 SG_ Cell9 m2 : 32|12@1+ (1,405) [405|4500] "" Vector__XXX
 SG_ Cell6 m1 : 32|12@1+ (1,405) [405|4500] "" Vector__XXX
 SG_ Cell3 m0 : 32|12@1+ (1,405) [405|4500] "" Vector__XXX
 SG_ Cell18 m5 : 32|12@1+ (1,405) [405|4500] "" Vector__XXX
 SG_ Cell15 m4 : 32|12@1+ (1,405) [405|4500] "" Vector__XXX
 SG_ Cell12 m3 : 32|12@1+ (1,405) [405|4500] "" Vector__XXX
 SG_ CellTemp3 m6 : 24|8@1+ (1,-40) [-40|140] "" Vector__XXX
 SG_ Cell8 m2 : 20|12@1+ (1,405) [405|4500] "" Vector__XXX
 SG_ Cell5 m1 : 20|12@1+ (1,405) [405|4500] "" Vector__XXX
 SG_ Cell2 m0 : 20|12@1+ (1,405) [405|4500] "" Vector__XXX
 SG_ Cell17 m5 : 20|12@1+ (1,405) [405|4500] "" Vector__XXX
 SG_ Cell14 m4 : 20|12@1+ (1,405) [405|4500] "" Vector__XXX
 SG_ Cell11 m3 : 20|12@1+ (1,405) [405|4500] "" Vector__XXX
 SG_ CellTemp2 m6 : 16|8@1+ (1,-40) [-40|140] "" Vector__XXX
 SG_ CellTemp1 m6 : 8|8@1+ (1,-40) [-40|140] "" Vector__XXX
 SG_ Cell7 m2 : 8|12@1+ (1,405) [405|4500] "" Vector__XXX
 SG_ Cell4 m1 : 8|12@1+ (1,405) [405|4500] "" Vector__XXX
 SG_ Cell16 m5 : 8|12@1+ (1,405) [405|4500] "" Vector__XXX
 SG_ Cell13 m4 : 8|12@1+ (1,405) [405|4500] "" Vector__XXX
 SG_ Cell10 m3 : 8|12@1+ (1,405) [405|4500] "" Vector__XXX
 SG_ Cell1 m0 : 8|12@1+ (1,405) [405|4500] "" Vector__XXX
 SG_ Cell_Cnt : 4|4@1+ (1,0) [0|15] "" Vector__XXX
 SG_ Cell_Idx M : 0|4@1+ (1,0) [0|4095] "" Vector__XXX

BO_ 1120 BMS_TX_STATE_1: 7 Vector__XXX
 SG_ CPU_2_Load : 48|8@1+ (1,0) [0|255] "" Vector__XXX
 SG_ CPU_1_Load : 40|8@1+ (1,0) [0|255] "" Vector__XXX
 SG_ CPU_0_Load : 32|8@1+ (1,0) [0|255] "" Vector__XXX
 SG_ Uptime_ms : 0|32@1+ (1,0) [0|4294970000.0] "" Vector__XXX

BO_ 1121 BMS_TX_STATE_2: 4 Vector__XXX
 SG_ DEM_Present : 15|1@1+ (1,0) [0|1] "" Vector__XXX
 SG_ DEM_Code : 0|15@1+ (1,0) [0|32767] "" Vector__XXX

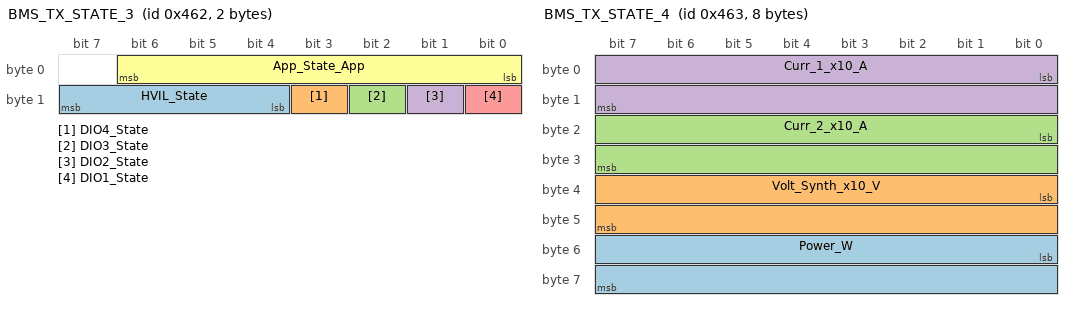
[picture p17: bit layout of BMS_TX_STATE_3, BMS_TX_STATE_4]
BO_ 1122 BMS_TX_STATE_3: 2 Vector__XXX
 SG_ HVIL_State : 12|4@1+ (1,0) [0|0] "" Vector__XXX
 SG_ DIO4_State : 11|1@1+ (1,0) [0|0] "" Vector__XXX
 SG_ DIO3_State : 10|1@1+ (1,0) [0|0] "" Vector__XXX
 SG_ DIO2_State : 9|1@1+ (1,0) [0|0] "" Vector__XXX
 SG_ DIO1_State : 8|1@1+ (1,0) [0|0] "" Vector__XXX
 SG_ App_State_App : 0|7@1+ (1,0) [0|255] "" Vector__XXX

BO_ 1123 BMS_TX_STATE_4: 8 Vector__XXX
 SG_ Power_W : 48|16@1- (1,0) [0|0] "" Vector__XXX
 SG_ Volt_Synth_x10_V : 32|16@1+ (0.03052,0) [0|2000.13] "" Vector__XXX
 SG_ Curr_2_x10_A : 16|16@1- (0.03052,0) [-1000.08|1000.05] "" Vector__XXX
 SG_ Curr_1_x10_A : 0|16@1- (0.03052,0) [-1000.08|1000.05] "" Vector__XXX

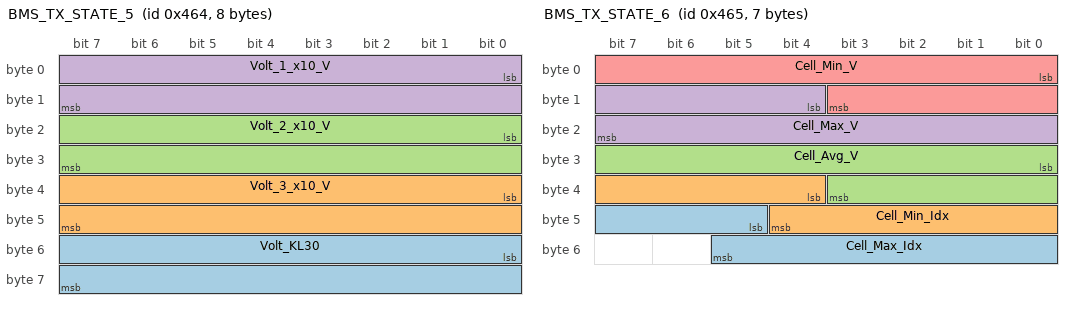
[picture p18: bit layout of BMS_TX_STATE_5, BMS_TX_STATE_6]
BO_ 1124 BMS_TX_STATE_5: 8 Vector__XXX
 SG_ Volt_KL30 : 48|16@1+ (1,0) [-32768|32767] "" Vector__XXX
 SG_ Volt_3_x10_V : 32|16@1- (0.03052,0) [-1000.08|1000.05] "" Vector__XXX
 SG_ Volt_2_x10_V : 16|16@1- (0.03052,0) [-1000.08|1000.05] "" Vector__XXX
 SG_ Volt_1_x10_V : 0|16@1- (0.03052,0) [-1000.08|1000.05] "" Vector__XXX

BO_ 1125 BMS_TX_STATE_6: 7 Vector__XXX
 SG_ Cell_Max_Idx : 45|9@1+ (1,0) [0|511] "" Vector__XXX
 SG_ Cell_Min_Idx : 36|9@1+ (1,0) [0|511] "" Vector__XXX
 SG_ Cell_Avg_V : 24|12@1+ (1,405) [405|4500] "" Vector__XXX
 SG_ Cell_Max_V : 12|12@1+ (1,405) [405|4500] "" Vector__XXX
 SG_ Cell_Min_V : 0|12@1+ (1,405) [405|4500] "" Vector__XXX

BO_ 1126 BMS_TX_STATE_7: 4 Vector__XXX
 SG_ Temp_4_degC : 24|8@1+ (1,-50) [-50|205] "" Vector__XXX
 SG_ Temp_3_degC : 16|8@1+ (1,-50) [-50|205] "" Vector__XXX
 SG_ Temp_2_degC : 8|8@1+ (1,-50) [-50|205] "" Vector__XXX
 SG_ Temp_1_degC : 0|8@1+ (1,-50) [-50|205] "" Vector__XXX

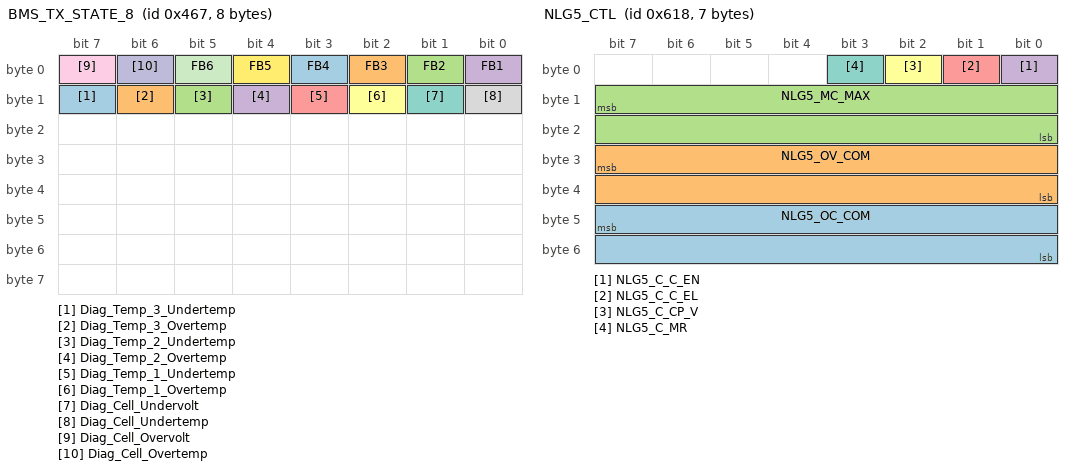
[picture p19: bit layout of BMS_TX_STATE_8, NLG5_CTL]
BO_ 1127 BMS_TX_STATE_8: 8 Vector__XXX
 SG_ Diag_Temp_3_Undertemp : 15|1@1- (1,0) [0|1] "" Vector__XXX
 SG_ Diag_Temp_3_Overtemp : 14|1@1- (1,0) [0|1] "" Vector__XXX
 SG_ Diag_Temp_2_Undertemp : 13|1@1- (1,0) [0|1] "" Vector__XXX
 SG_ Diag_Temp_2_Overtemp : 12|1@1- (1,0) [0|1] "" Vector__XXX
 SG_ Diag_Temp_1_Undertemp : 11|1@1- (1,0) [0|1] "" Vector__XXX
 SG_ Diag_Temp_1_Overtemp : 10|1@1- (1,0) [0|1] "" Vector__XXX
 SG_ Diag_Cell_Undervolt : 9|1@1- (1,0) [0|1] "" Vector__XXX
 SG_ Diag_Cell_Undertemp : 8|1@1- (1,0) [0|1] "" Vector__XXX
 SG_ Diag_Cell_Overvolt : 7|1@1- (1,0) [0|1] "" Vector__XXX
 SG_ Diag_Cell_Overtemp : 6|1@1- (1,0) [0|1] "" Vector__XXX
 SG_ FB6 : 5|1@1+ (1,0) [0|1] "" Vector__XXX
 SG_ FB5 : 4|1@1+ (1,0) [0|1] "" Vector__XXX
 SG_ FB4 : 3|1@1+ (1,0) [0|1] "" Vector__XXX
 SG_ FB3 : 2|1@1+ (1,0) [0|0] "" Vector__XXX
 SG_ FB2 : 1|1@1+ (1,0) [0|1] "" Vector__XXX
 SG_ FB1 : 0|1@1+ (1,0) [0|1] "" Vector__XXX

BO_ 1128 BMS_TX_STATE_9: 3 Vector__XXX
 SG_ Cell_Temp_Min_degC : 16|8@1- (1,-50) [-128|127] "" Vector__XXX
 SG_ Cell_Temp_Max_degC : 8|8@1- (1,-50) [-128|127] "" Vector__XXX
 SG_ Cell_Temp_Avg_degC : 0|8@1- (1,-50) [-128|127] "" Vector__XXX

BO_ 1129 BMS_TX_STATE_10: 4 Vector__XXX
 SG_ IMD_Res_Neg_kohm : 16|16@1+ (1,0) [0|65535] "" Vector__XXX
 SG_ IMD_Res_Pos_kohm : 0|16@1+ (1,0) [0|65535] "" Vector__XXX

BO_ 1136 BMS_TX_STATE_11: 8 Vector__XXX
 SG_ SOH : 8|8@1+ (1,0) [0|255] "" Vector__XXX
 SG_ SOC : 0|8@1+ (1,0) [0|255] "" Vector__XXX

BO_ 1552 NLG5_ST: 4 Control
 SG_ NLG5_S_AAC : 31|1@0+ (1,0) [0|1] "" Vector__XXX
 SG_ NLG5_S_L_MC_MAX : 16|1@0+ (1,0) [0|1] "" Vector__XXX
 SG_ NLG5_S_L_OC_MAX : 17|1@0+ (1,0) [0|1] "" Vector__XXX
 SG_ NLG5_S_L_MO_MAX : 18|1@0+ (1,0) [0|1] "" Vector__XXX
 SG_ NLG5_S_L_T_CPRIM : 19|1@0+ (1,0) [0|1] "" Vector__XXX
 SG_ NLG5_S_L_T_POW : 20|1@0+ (1,0) [0|1] "" Vector__XXX
 SG_ NLG5_S_L_T_DIO : 21|1@0+ (1,0) [0|1] "" Vector__XXX
 SG_ NLG5_S_L_T_TR : 22|1@0+ (1,0) [0|1] "" Vector__XXX
 SG_ NLG5_S_L_T_BATT : 23|1@0+ (1,0) [0|1] "" Vector__XXX
 SG_ NLG5_S_BPD_I : 8|1@0+ (1,0) [0|1] "" Vector__XXX
 SG_ NLG5_S_BPD_II : 9|1@0+ (1,0) [0|1] "" Vector__XXX
 SG_ NLG5_S_L_OV : 10|1@0+ (1,0) [0|1] "" Vector__XXX
 SG_ NLG5_S_L_OC : 11|1@0+ (1,0) [0|1] "" Vector__XXX
 SG_ NLG5_S_L_MC : 12|1@0+ (1,0) [0|1] "" Vector__XXX
 SG_ NLG5_S_L_PI : 13|1@0+ (1,0) [0|1] "" Vector__XXX
 SG_ NLG5_S_L_CP : 14|1@0+ (1,0) [0|1] "" Vector__XXX
 SG_ NLG5_S_L_PMAX : 15|1@0+ (1,0) [0|1] "" Vector__XXX
 SG_ NLG5_S_HE : 0|1@0+ (1,0) [0|1] "" Vector__XXX
 SG_ NLG5_S_ERR : 1|1@0+ (1,0) [0|1] "" Vector__XXX
 SG_ NLG5_S_WAR : 2|1@0+ (1,0) [0|1] "" Vector__XXX
 SG_ NLG5_S_FAN : 3|1@0+ (1,0) [0|1] "" Vector__XXX
 SG_ NLG5_S_EUM : 4|1@0+ (1,0) [0|1] "" Vector__XXX
 SG_ NLG5_S_UM_I : 5|1@0+ (1,0) [0|1] "" Vector__XXX
 SG_ NLG5_S_UM_II : 6|1@0+ (1,0) [0|1] "" Vector__XXX
 SG_ NLG5_S_CP_DT : 7|1@0+ (1,0) [0|1] "" Vector__XXX

BO_ 1553 NLG5_ACT_I: 8 Control
 SG_ NLG5_OC_ACT : 55|16@0+ (0.01,0) [0|150] "A" Vector__XXX
 SG_ NLG5_OV_ACT : 39|16@0+ (0.1,0) [0|1000] "V" Vector__XXX
 SG_ NLG5_MV_ACT : 23|16@0+ (0.1,0) [0|500] "V" Vector__XXX
 SG_ NLG5_MC_ACT : 7|16@0+ (0.01,0) [0|50] "A" Vector__XXX

BO_ 1554 NLG5_ACT_II: 8 Control
 SG_ NLG5_ABV : 31|8@0+ (0.1,0) [0|25] "V" Vector__XXX
 SG_ NLG5_S_MC_M_PI : 23|8@0+ (0.1,0) [0|20] "A" Vector__XXX
 SG_ NLG5_S_MC_M_CP : 7|16@0+ (0.1,0) [0|100] "A" Vector__XXX

BO_ 1555 NLG5_TEMP: 8 Control
 SG_ NLG5_TMP_EXT3 : 55|16@0+ (0.1,0) [-40|300] "Â°C" Vector__XXX
 SG_ NLG5_TMP_EXT2 : 39|16@0+ (0.1,0) [-40|300] "Â°C" Vector__XXX
 SG_ NLG5_TMP_EXT1 : 23|16@0+ (0.1,0) [-40|300] "Â°C" Vector__XXX
 SG_ NLG5_P_TMP : 7|16@0+ (0.1,0) [-40|300] "Â°C" Vector__XXX

BO_ 1556 NLG5_ERR: 5 Control
 SG_ NLG5_W_PL_MV : 32|1@0+ (1,0) [0|1] "" Vector__XXX
 SG_ NLG5_W_PL_BV : 33|1@0+ (1,0) [0|1] "" Vector__XXX
 SG_ NLG5_W_PL_IT : 34|1@0+ (1,0) [0|1] "" Vector__XXX
 SG_ NLG5_W_C_VOR : 35|1@0+ (1,0) [0|1] "" Vector__XXX
 SG_ NLG5_W_CM_NA : 36|1@0+ (1,0) [0|1] "" Vector__XXX
 SG_ NLG5_W_OD : 38|1@0+ (1,0) [0|1] "" Vector__XXX
 SG_ NLG5_W_SC_M : 39|1@0+ (1,0) [0|1] "" Vector__XXX
 SG_ NLG5_E_C_TX : 24|1@0+ (1,0) [0|1] "" Vector__XXX
 SG_ NLG5_E_C_RX : 25|1@0+ (1,0) [0|1] "" Vector__XXX
 SG_ NLG5_E_SDT_BT : 26|1@0+ (1,0) [0|1] "" Vector__XXX
 SG_ NLG5_E_SDT_BV : 27|1@0+ (1,0) [0|1] "" Vector__XXX
 SG_ NLG5_E_SDT_AH : 28|1@0+ (1,0) [0|1] "" Vector__XXX
 SG_ NLG5_E_SDT_CT : 29|1@0+ (1,0) [0|1] "" Vector__XXX
 SG_ NLG5_E_F_CRC : 16|1@0+ (1,0) [0|1] "" Vector__XXX
 SG_ NLG5_E_NV_CRC : 17|1@0+ (1,0) [0|1] "" Vector__XXX
 SG_ NLG5_E_ES_CRC : 18|1@0+ (1,0) [0|1] "" Vector__XXX
 SG_ NLG5_E_EP_CRC : 19|1@0+ (1,0) [0|1] "" Vector__XXX
 SG_ NLG5_E_WDT : 20|1@0+ (1,0) [0|1] "" Vector__XXX
 SG_ NLG5_E_INIT : 21|1@0+ (1,0) [0|1] "" Vector__XXX
 SG_ NLG5_E_C_TO : 22|1@0+ (1,0) [0|1] "" Vector__XXX
 SG_ NLG5_E_C_OFF : 23|1@0+ (1,0) [0|1] "" Vector__XXX
 SG_ NLG5_E_B_P : 8|1@0+ (1,0) [0|1] "" Vector__XXX
 SG_ NLG5_E_T_C : 9|1@0+ (1,0) [0|1] "" Vector__XXX
 SG_ NLG5_E_T_POW : 10|1@0+ (1,0) [0|1] "" Vector__XXX
 SG_ NLG5_E_T_DIO : 11|1@0+ (1,0) [0|1] "" Vector__XXX
 SG_ NLG5_E_T_TR : 12|1@0+ (1,0) [0|1] "" Vector__XXX
 SG_ NLG5_E_T_EXT1 : 13|1@0+ (1,0) [0|1] "" Vector__XXX
 SG_ NLG5_E_T_EXT2 : 14|1@0+ (1,0) [0|1] "" Vector__XXX
 SG_ NLG5_E_T_EXT3 : 15|1@0+ (1,0) [0|1] "" Vector__XXX
 SG_ NLG5_E_OOV : 0|1@0+ (1,0) [0|1] "" Vector__XXX
 SG_ NLG5_E_MOV_II : 1|1@0+ (1,0) [0|1] "" Vector__XXX
 SG_ NLG5_E_MOV_I : 2|1@0+ (1,0) [0|1] "" Vector__XXX
 SG_ NLG5_E_SC : 3|1@0+ (1,0) [0|1] "" Vector__XXX
 SG_ NLG5_E_P_OM : 4|1@0+ (1,0) [0|1] "" Vector__XXX
 SG_ NLG5_E_P_MV : 5|1@0+ (1,0) [0|1] "" Vector__XXX
 SG_ NLG5_E_OF : 6|1@0+ (1,0) [0|1] "" Vector__XXX
 SG_ NLG5_E_MF : 7|1@0+ (1,0) [0|1] "" Vector__XXX

BO_ 1560 NLG5_CTL: 7 Vector__XXX
 SG_ NLG5_OC_COM : 47|16@0+ (0.1,0) [0|150] "A"  Control
 SG_ NLG5_OV_COM : 31|16@0+ (0.1,0) [0|1000] "V"  Control
 SG_ NLG5_MC_MAX : 15|16@0+ (0.1,0) [0|50] "A"  Control
 SG_ NLG5_C_C_EN : 0|1@0+ (1,0) [0|1] ""  Control
 SG_ NLG5_C_C_EL : 1|1@0+ (1,0) [0|1] ""  Control
 SG_ NLG5_C_CP_V : 2|1@0+ (1,0) [0|1] ""  Control
 SG_ NLG5_C_MR : 3|1@0+ (1,0) [0|1] ""  Control

BO_ 1816 NLG5_DIAG_RX: 8 Vector__XXX
 SG_ LAD_D_ParamRq : 7|64@0+ (1,0) [0|0] ""  Control

BO_ 1818 NLG5_DIAG_TX: 8 Control
 SG_ LAD_D_ParamRp : 7|64@0+ (1,0) [0|0] "" Vector__XXX

CM_ BU_ STEER "The Steering Input MOdule";
CM_ BU_ PEDAL "The Drivers Sensor Board";
CM_ BU_ TER_CMDS "The Command Subsystem For TeR Vehicle";
CM_ BU_ FRONT_AXLE "The Board for Front axle sensors";
CM_ BU_ IMU "TeRs Inertial Measurement Unit";
CM_ BU_ LVBMS "The LV battery Management System";
CM_ BU_ ECU "The VCU for TeR Vehicle";
CM_ BU_ CHARGER "The Control Module for TeR Charger";
CM_ BU_ REFRI "The refrigeration module";
CM_ BO_ 1 "FUNCTION INDEX";
CM_ BO_ 2 "RESPONSE of a command";
CM_ BO_ 1552 "NLG5 Status (cycle_time: 100)";
CM_ SG_ 1552 NLG5_S_AAC "AUX 12 V Automatic Charging Active";
CM_ SG_ 1552 NLG5_S_L_MC_MAX "Output power limited by maximum mains current capability of NLG5";
CM_ SG_ 1552 NLG5_S_L_OC_MAX "Output power limited by maximum output current capability of NLG5";
CM_ SG_ 1552 NLG5_S_L_MO_MAX "Output power limited by maximum output voltage capability of NLG5";
CM_ SG_ 1552 NLG5_S_L_T_CPRIM "Output power limited by temperature of primary capacitors";
CM_ SG_ 1552 NLG5_S_L_T_POW "Output power limited by temperature of power stage";
CM_ SG_ 1552 NLG5_S_L_T_DIO "Output power limited by temperature of diodes";
CM_ SG_ 1552 NLG5_S_L_T_TR "Output power limited by temperature of transformer";
CM_ SG_ 1552 NLG5_S_L_T_BATT "Output power limited by battery temperature";
CM_ SG_ 1552 NLG5_S_BPD_I "Bypass detection bit 1; 00: no bypass, 01: DC bypass detected, 10: AC bypass in phase, 11: AC bypass not in phase";
CM_ SG_ 1552 NLG5_S_BPD_II "Bypass detection bit 2; 00: no bypass, 01: DC bypass detected, 10: AC bypass in phase, 11: AC bypass not in phase";
CM_ SG_ 1552 NLG5_S_L_OV "Output power limited by battery output voltage limit";
CM_ SG_ 1552 NLG5_S_L_OC "Output power limited by battery output current limit";
CM_ SG_ 1552 NLG5_S_L_MC "Output power limited by mains current limit";
CM_ SG_ 1552 NLG5_S_L_PI "Output power limited by analogue input 'power indicator' (PI) limit";
CM_ SG_ 1552 NLG5_S_L_CP "Output power limited by control pilot signal (SAE J1772)";
CM_ SG_ 1552 NLG5_S_L_PMAX "Output power limited by maximum power capability of NLG5";
CM_ SG_ 1552 NLG5_S_HE "Indicates if hardware enabled, i.e. a high or low signal is fed to the 'Power On' pin (pin3 of control connector)";
CM_ SG_ 1552 NLG5_S_ERR "An error has been detected, red LED is ON, no power is output";
CM_ SG_ 1552 NLG5_S_WAR "Warning condition on, i.e. charging power limited due to any limiting condition; red LED is blinking";
CM_ SG_ 1552 NLG5_S_FAN "Charger cooling fan is active";
CM_ SG_ 1552 NLG5_S_EUM "European mains input detected (230 V, 50 Hz)";
CM_ SG_ 1552 NLG5_S_UM_I "US mains level 1 (120 V AC / 60 Hz) detected";
CM_ SG_ 1552 NLG5_S_UM_II "US mains level 2 (240 V AC / 60 Hz) detected";
CM_ SG_ 1552 NLG5_S_CP_DT "Control pilot signal (SAE J1772) detected";
CM_ BO_ 1553 "NLG5 Actual Values I (cycle_time: 100)";
CM_ SG_ 1553 NLG5_OC_ACT "Output current to the battery";
CM_ SG_ 1553 NLG5_OV_ACT "Actual battery output voltage";
CM_ SG_ 1553 NLG5_MV_ACT "Actual mains voltage";
CM_ SG_ 1553 NLG5_MC_ACT "Actual mains current";
CM_ BO_ 1554 "NLG5 Actual Values II (cycle_time: 100)";
CM_ SG_ 1554 NLG5_ABV "Aux battery voltage";
CM_ SG_ 1554 NLG5_S_MC_M_PI "Value of mains current limit, commanded by the 'power indicator' (PI) analogue input signal";
CM_ SG_ 1554 NLG5_S_MC_M_CP "Value of mains current limit, commanded by the control pilot (SAE J1772) signal";
CM_ BO_ 1555 "NLG5 Temp Feedback (cycle_time: 1000)";
CM_ SG_ 1555 NLG5_TMP_EXT3 "Value of external battery temperature sensor #3 (if connected and enabled)";
CM_ SG_ 1555 NLG5_TMP_EXT2 "Value of external battery temperature sensor #2 (if connected and enabled)";
CM_ SG_ 1555 NLG5_TMP_EXT1 "Value of external battery temperature sensor #1 (if connected and enabled)";
CM_ SG_ 1555 NLG5_P_TMP "Power stage temperature";
CM_ BO_ 1556 "NLG5 Errors/Warnings (cycle_time: 1000)";
CM_ SG_ 1556 NLG5_W_PL_MV "Output power limited by low mains voltage";
CM_ SG_ 1556 NLG5_W_PL_BV "Output power limited by low battery voltage";
CM_ SG_ 1556 NLG5_W_PL_IT "Output power limited by charger internal excessive temperature";
CM_ SG_ 1556 NLG5_W_C_VOR "Commanded value is out of specified range; max or min applicable value is assumed instead";
CM_ SG_ 1556 NLG5_W_CM_NA "NLG5 control message not active";
CM_ SG_ 1556 NLG5_W_OD "LED output driver defective, LEDs can't be controlled by NLG5 anymore. Charging is still possible.";
CM_ SG_ 1556 NLG5_W_SC_M "Save-Charging-Mode reduces primary current to 3.95 A as long as one of the four internal temperature sensors indicates -18Â° C or less";
CM_ SG_ 1556 NLG5_E_C_TX "CAN transmit buffer >127";
CM_ SG_ 1556 NLG5_E_C_RX "CAN receiver buffer >127";
CM_ SG_ 1556 NLG5_E_SDT_BT "Emergency shutdown threshold 'Battery Temperature' is exceeded; see ChargeStar help section 'protective features'; error can only be cleared by cycling power ON-OFF-ON";
CM_ SG_ 1556 NLG5_E_SDT_BV "Emergency shutdown threshold 'Battery Voltage' is exceeded; see ChargeStar help section 'protective features'; error can only be cleared by cycling power ON-OFF-ON";
CM_ SG_ 1556 NLG5_E_SDT_AH "Emergency shutdown threshold 'Amp Hours' is exceeded; see ChargeStar help section 'protective features'; error can only be cleared by cycling power ON-OFF-ON";
CM_ SG_ 1556 NLG5_E_SDT_CT "Emergency shutdown threshold 'Charging Time' is exceeded; see ChargeStar help section 'protective features'; error can only be cleared by cycling power ON-OFF-ON";
CM_ SG_ 1556 NLG5_E_F_CRC "Flash memory checksum failure";
CM_ SG_ 1556 NLG5_E_NV_CRC "NVSRAM check sum failure; contains most of the scaling & calibration values, CAN ID's and charging profile etc.";
CM_ SG_ 1556 NLG5_E_ES_CRC "Sys EEPROM checksum failure";
CM_ SG_ 1556 NLG5_E_EP_CRC "Pow EEPROM checksum failure";
CM_ SG_ 1556 NLG5_E_WDT "Internal Watchdog Timeout";
CM_ SG_ 1556 NLG5_E_INIT "Initialisation error";
CM_ SG_ 1556 NLG5_E_C_TO "CAN timeout, no control message received for >300 ms";
CM_ SG_ 1556 NLG5_E_C_OFF "CAN off, transmit buffer >255";
CM_ SG_ 1556 NLG5_E_B_P "Wrong battery polarity; error can only be cleared by cycling power ON-OFF-ON";
CM_ SG_ 1556 NLG5_E_T_C "Temperature sensor for prim capacitor defective";
CM_ SG_ 1556 NLG5_E_T_POW "Temperature sensor for prim power stage defective";
CM_ SG_ 1556 NLG5_E_T_DIO "Temperature sensor for diodes defective";
CM_ SG_ 1556 NLG5_E_T_TR "Temperature sensor for transformer defective";
CM_ SG_ 1556 NLG5_E_T_EXT1 "Ext. temperature sensor 1 defective (if enabled)";
CM_ SG_ 1556 NLG5_E_T_EXT2 "Ext. temperature sensor 2 defective (if enabled), ext. temperature sensor 2 defective (if enabled)";
CM_ SG_ 1556 NLG5_E_T_EXT3 "Ext. temperature sensor 3 defective (if enabled)";
CM_ SG_ 1556 NLG5_E_OOV "Battery output over-voltage; error can only be cleared by cycling power ON-OFF-ON";
CM_ SG_ 1556 NLG5_E_MOV_II "Mains over-voltage 2 detected";
CM_ SG_ 1556 NLG5_E_MOV_I "Mains over-voltage 1 detected";
CM_ SG_ 1556 NLG5_E_SC "Power stage short circuit condition detected; error can only be cleared by cycling power ON-OFF-ON";
CM_ SG_ 1556 NLG5_E_P_OM "Plausibility battery output voltage measurement wrong";
CM_ SG_ 1556 NLG5_E_P_MV "Plausibility mains voltage measurement wrong";
CM_ SG_ 1556 NLG5_E_OF "Output fuse defective";
CM_ SG_ 1556 NLG5_E_MF "Mains fuse defective";
CM_ BO_ 1560 "NLG5 Control (cycle_time: 100)";
CM_ SG_ 1560 NLG5_OC_COM "Desired battery current. Must always contain a valid value in order to keep on charging";
CM_ SG_ 1560 NLG5_OV_COM "Desired voltage to be output to the battery. Must always contain a valid value in order to keep on charging";
CM_ SG_ 1560 NLG5_MC_MAX "Maximum current to be drawn from the mains outlet, usually 16 A. Must always contain a valid value in order to keep on charging";
CM_ SG_ 1560 NLG5_C_C_EN "Must be ON to enable power stage of the charger";
CM_ SG_ 1560 NLG5_C_C_EL "Cycle this value 0-1-0 to clear all latched charger errors";
CM_ SG_ 1560 NLG5_C_CP_V "Special signal to tell a charging station equipped with the Control pilot interface (SAE J1772) to switch on the facility's ventilation (in order to get rid of battery gases like hydrogen, e.g.)";
CM_ SG_ 1560 NLG5_C_MR "Enables CP-State C to request mains voltage";
CM_ BO_ 1816 "NLG5 Diag Rx";
CM_ SG_ 1816 LAD_D_ParamRq "Diag requested data from host";
CM_ BO_ 1818 "NLG5 Diag Tx";

VAL_ 2147484162 HEX_SIZE 0 "" ;
VAL_ 2147484162 HEX_CRC 0 "" ;
VAL_ 2147484162 NODE_ID 0 "PEDAL" 1 "REFRI" 2 "LVBMS" 3 "ECU" 4 "STEER" ;
VAL_ 2147484162 BOOT_CMD 0 "BOOT_INIT" 1 "TRANSMIT_START" 2 "TRANSMIT_END" 3 "deprecated" ;
VAL_ 2147484161 NACK 0 "" ;
VAL_ 2147484161 ACK 0 "" ;
VAL_ 2147484161 PERCENT 0 "" ;
VAL_ 2147484161 BOOT_CMD 0 "ACK" 1 "NACK" 2 "PERCENT" ;
VAL_ 1 ONOFF 0 "OFF" 1 "ON" ;
VAL_ 1 CMD 14 "resetBMS" 1 "Calibrate_APPS_min" 2 "Calibrate_APPS_max" 5 "Calibrate_STEER_Leftest" 6 "Calibrate_STEER_Rightest" 8 "discharge" 9 "precharge" 10 "beep" 11 "ready2Drive" 0 "charge" 12 "startLog" 13 "endLog" ;
VAL_ 2 CODE 1 "OK" 2 "ERROR" 3 "INVALID_STATE" 4 "OUT_OF_RANGE" ;
VAL_ 18 CURRENT_OK 0 "FAULT" 1 "OK" ;
VAL_ 18 TEMPS_OK 0 "FAULT" 1 "OK" ;
VAL_ 18 VOLTAGES_OK 0 "FAULT" 1 "OK" ;
VAL_ 18 STATUS 0 "FAULT" 1 "OK" ;
VAL_ 37 STATE 0 "WAIT_SL" 1 "READY2PRECH" 2 "PRECHARGING" 3 "PRECHARGED" 4 "DRIVING" ;
VAL_ 2147483686 TRACTION_CONTROL 0 "OFF" ;
VAL_ 2147483686 SCS_ENABLE 0 "DISABLE" 1 "ENABLE" ;
VAL_ 2147483686 REGEN_TRQ_SLOPE 0 "" ;
VAL_ 2147483686 REGEN_THR_SPEED 0 "" ;
VAL_ 2147483686 REGEN_THR_RPM 0 "" ;
VAL_ 2147483686 REGEN_MODE 0 "APPS" 1 "BPPS" ;
VAL_ 2147483686 REGEN_MAX_POSITIVE_TRQ_THR 0 "" ;
VAL_ 2147483686 REGEN_MAX_TRQ 0 "" ;
VAL_ 2147483686 REGEN_MAX_CURRENT 0 "" ;
VAL_ 2147483686 REGEN_MAX_CELL_VOLT 0 "" ;
VAL_ 2147483686 REGEN_MAX_CELL_TEMP 0 "" ;
VAL_ 2147483686 REGEN_ENABLE 0 "ENABLE" 1 "DISABLE" ;
VAL_ 2147483686 LIMITER 0 "TORQUE" 1 "SPEED" 2 "POWER" ;
VAL_ 2147483686 FLAP_R_REVERSE 0 "NORMAL" 1 "REVERSE" ;
VAL_ 2147483686 FLAP_L_REVERSE 0 "NORMAL" 1 "REVERSE" ;
VAL_ 2147483686 FLAP_ENABLE 0 "OFF" 1 "ON" ;
VAL_ 2147483686 EEPROM 1 "CLEAR_AND_DEFAULT" 2 "READ" ;
VAL_ 2147483686 DRIVING_MODE 0 "LINEAL" 1 "TORQUE_VECTORING" ;
VAL_ 2147483686 ENTRY 0 "SCS_ENABLE" 1 "R2D_BRAKE_VAL" 2 "LIMITER" 3 "DRIVING_MODE" 4 "TRACTION_CONTROL" 5 "TRQV_KP" 6 "TRQV_KI" 7 "TRQV_KD" 8 "TRQ_LIMIT" 9 "EEPROM" 10 "FLAP_L_OFFSET" 11 "FLAP_R_OFFSET" 12 "FLAP_L_REVERSE" 13 "FLAP_R_REVERSE" 14 "FLAP_ENABLE" 15 "FLAP_PEDAL_SETPOINT" 17 "REGEN_ENABLE" 18 "REGEN_MAX_TRQ" 19 "REGEN_MAX_CELL_VOLT" 20 "REGEN_MAX_CELL_TEMP" 21 "REGEN_MAX_CURRENT" 22 "REGEN_THR_SPEED" 23 "REGEN_THR_RPM" 24 "REGEN_TRQ_SLOPE" 25 "REGEN_MODE" 26 "REGEN_MAX_POSITIVE_TRQ_THR" ;
VAL_ 2147483985 TARGET_TEMP_ACCU 0 "" ;
VAL_ 2147483985 POWER_ACCU 0 "OFF" 1 "ON" ;
VAL_ 2147483985 POWER 0 "OFF" 1 "ON" ;
VAL_ 2147483985 MODE_ACCU 0 "AUTO" 1 "MANUAL" ;
VAL_ 2147483985 MODE 0 "AUTO" 1 "MANUAL" ;
VAL_ 2147483985 ENTRY 0 "POWER" 1 "INTENSITY" 2 "MODE" 3 "TARGET_TEMP" 4 "POWER_ACCU" 5 "INTENSITY_ACCU" 6 "MODE_ACCU" 7 "TARGET_TEMP_ACCU" ;
VAL_ 2147483987 MODE 0 "AUTO" 1 "MANUAL" ;
VAL_ 517 State 0 "IDLE" 1 "READY" 2 "PRECHARGING" 3 "PRECHARGED" 4 "CHARGING" ;
VAL_ 864 Contactor_4_Req 1 "Contactor ON" 0 "Contactor OFF" ;
VAL_ 864 Contactor_3_Req 1 "Contactor ON" 0 "Contactor OFF" ;
VAL_ 864 Contactor_2_Req 1 "Contactor ON" 0 "Contactor OFF" ;
VAL_ 864 Contactor_1_Req 1 "Contactor ON" 0 "Contactor OFF" ;
VAL_ 864 App_State_Req 1 "INIT" 2 "POST" 3 "STANDBY" 4 "HV_READY_PRECHARGE" 5 "HV_READY" 6 "HV_CHARGE_PRECHARGE" 7 "HV_CHARGE" 8 "HV_SHUTDOWN" 9 "SOFTFAULT" 10 "HARDFAULT" ;
VAL_ 1122 DIO4_State 1 "HIGH" 0 "LOW" ;
VAL_ 1122 DIO3_State 1 "HIGH" 0 "LOW" ;
VAL_ 1122 DIO2_State 1 "HIGH" 0 "LOW" ;
VAL_ 1122 DIO1_State 1 "HIGH" 0 "LOW" ;
VAL_ 1122 App_State_App 12 "Off" 11 "Shutdown" 10 "Fault Hard" 9 "Fault Soft" 8 "HV Shutdown" 7 "HV Charge" 6 "HV Precharge Charge" 5 "HV Ready" 4 "HV Precharge Ready" 3 "Standby" 2 "POST" 1 "Init" 0 "Unknown" ;
